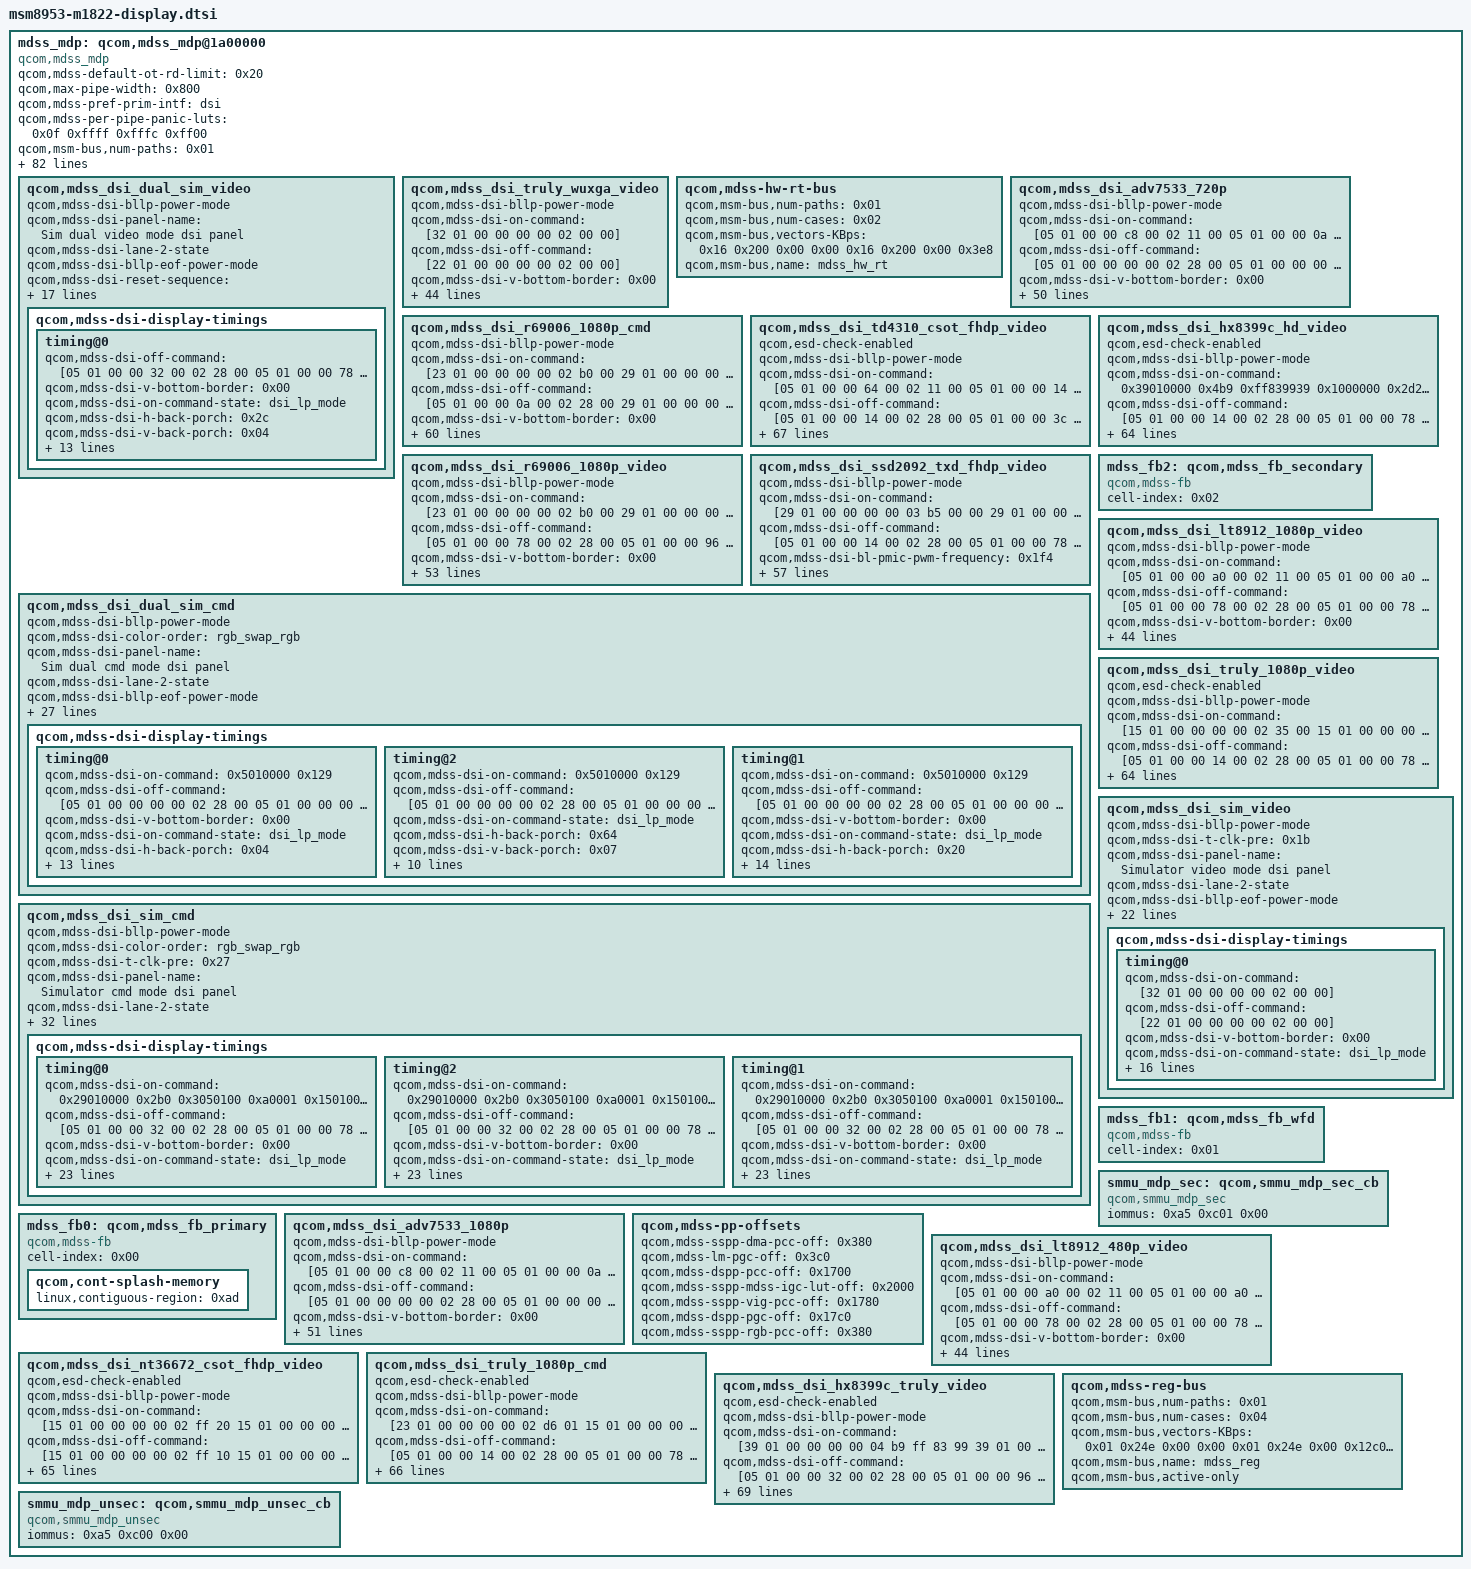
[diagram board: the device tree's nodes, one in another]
		mdss_mdp: qcom,mdss_mdp@1a00000 {
			qcom,mdss-default-ot-rd-limit = <0x20>;
			qcom,max-pipe-width = <0x800>;
			qcom,mdss-pref-prim-intf = "dsi";
			qcom,mdss-per-pipe-panic-luts = <0x0f 0xffff 0xfffc 0xff00>;
			qcom,msm-bus,num-paths = <0x01>;
			qcom,msm-bus,num-cases = <0x03>;
			qcom,mdss-wb-off = <0x65000 0x66000>;
			qcom,mdss-pipe-dma-xin-id = <0x02>;
			qcom,regs-dump-mdp = <0x1000 0x1454 0x2000 0x2064 0x2200 0x2264 0x2400 0x2464 0x5000 0x5150 0x5200 0x5230 0x15000 0x15150 0x17000 0x17150 0x25000 0x25150 0x35000 0x35150 0x45000 0x452bc 0x46000 0x462bc 0x55000 0x5522c 0x65000 0x652c0 0x66000 0x662c0 0x6b800 0x6ba68 0x6c000 0x6c268 0x71000 0x710d4 0x71800 0x718d4>;
			compatible = "qcom,mdss_mdp";
			qcom,mdss-prefill-pingpong-buffer-pixels = <0x1000>;
			clocks = <0x29 0xbfb92ed3 0x29 0x668f51de 0x29 0x6dc1f8f1 0xac 0x588460a4 0x29 0x32a09f1f>;
			qcom,mdss-default-ot-wr-limit = <0x10>;
			qcom,msm-bus,vectors-KBps = <0x16 0x200 0x00 0x00 0x16 0x200 0x00 0x61a800 0x16 0x200 0x00 0x61a800>;
			qcom,mdss-vbif-qos-nrt-setting = <0x01 0x01 0x01 0x01>;
			qcom,mdss-has-pingpong-split;
			reg-names = "mdp_phys", "vbif_phys";
			qcom,regs-dump-names-mdp = "MDP", "CTL_0", "CTL_1", "CTL_2", "VIG0_SSPP", "VIG0", "RGB0_SSPP", "RGB1_SSPP", "DMA0_SSPP", "CURSOR0_SSPP", "LAYER_0", "LAYER_1", "DSPP_0", "WB_0", "WB_2", "INTF_1", "INTF_2", "PP_0", "PP_1";
			qcom,mdss-slave-pingpong-off = "", "\a0";
			qcom,mdss-pipe-vig-off = <0x5000>;
			qcom,mdss-pipe-cursor-off = <0x35000>;
			qcom,max-mixer-width = <0x800>;
			qcom,mdss-pipe-rgb-clk-ctrl-offsets = <0x2ac 0x04 0x08 0x2b4 0x04 0x08>;
			qcom,mdss-ab-factor = <0x01 0x01>;
			qcom,mdss-pipe-rgb-xin-id = <0x01 0x05>;
			qcom,mdss-has-panic-ctrl;
			qcom,mdp-settings = <0x506c 0x00 0x1506c 0x00 0x1706c 0x00 0x2506c 0x00>;
			qcom,mdss-idle-power-collapse-enabled;
			clock-names = "iface_clk", "bus_clk", "core_clk_src", "core_clk", "vsync_clk";
			qcom,mdss-pipe-vig-xin-id = <0x00>;
			qcom,mdss-prefill-scaler-buffer-lines-bilinear = <0x02>;
			qcom,mdss-cdm-off = <0x7a200>;
			qcom,mdss-pipe-vig-clk-ctrl-offsets = <0x2ac 0x00 0x00>;
			qcom,mdss-pipe-dma-clk-ctrl-offsets = <0x2ac 0x08 0x0c>;
			qcom,mdss-ppb-off = <0x330>;
			qcom,mdss-pipe-cursor-clk-ctrl-offsets = <0x3a8 0x10 0x0f>;
			qcom,msm-bus,name = "mdss_mdp";
			qcom,vbif-settings = <0xd0 0x10>;
			qcom,max-bandwidth-high-kbps = <0x33e140>;
			qcom,max-bandwidth-low-kbps = <0x33e140>;
			qcom,mdss-prefill-y-buffer-bytes = <0x00>;
			qcom,mdss-rot-downscale-min = <0x02>;
			qcom,mdss-dspp-off = <0x55000>;
			interrupts = <0x00 0x48 0x00>;
			qcom,mdss-highest-bank-bit = <0x01>;
			qcom,mdss-prefill-scaler-buffer-lines-caf = <0x04>;
			qcom,mdss-wfd-mode = "intf";
			qcom,mdss-pingpong-off = <0x71000 0x71800>;
			qcom,mdss-has-non-scalar-rgb;
			phandle = <0xb2>;
			qcom,mdss-mixer-intf-off = <0x45000 0x46000>;
			qcom,max-clk-rate = <0x17d78400>;
			qcom,mdss-rot-block-size = <0x40>;
			qcom,mdss-rot-downscale-max = <0x10>;
			qcom,mdss-mdp-reg-offset = <0x1000>;
			qcom,mdss-has-rotator-downscale;
			qcom,mdss-ib-factor = <0x01 0x01>;
			qcom,mdss-has-decimation;
			qcom,mdss-pipe-cursor-xin-id = <0x07>;
			vdd-supply = <0xab>;
			reg = <0x1a00000 0x90000 0x1ab0000 0x1040>;
			qcom,mdss-clk-factor = <0x69 0x64>;
			qcom,mdss-vbif-qos-rt-setting = <0x01 0x02 0x02 0x02>;
			qcom,mdss-intf-off = <0x6b000 0x6b800 0x6c000>;
			qcom,mdss-pipe-dma-off = <0x25000>;
			qcom,mdss-pipe-rgb-off = <0x15000 0x17000>;
			linux,phandle = <0xb2>;
			qcom,mdss-ctl-off = <0x2000 0x2200 0x2400>;
			qcom,max-bw-settings = <0x01 0x33e140 0x02 0x2f4d60>;
			qcom,max-bandwidth-per-pipe-kbps = <0x231860>;
			qcom,mdss-prefill-outstanding-buffer-bytes = <0x00>;
			qcom,mdss-prefill-post-scaler-buffer-pixels = <0x800>;

			qcom,mdss_dsi_dual_sim_video {
				qcom,mdss-dsi-bllp-power-mode;
				qcom,mdss-dsi-panel-name = "Sim dual video mode dsi panel";
				qcom,mdss-dsi-lane-2-state;
				qcom,mdss-dsi-bllp-eof-power-mode;
				qcom,mdss-dsi-reset-sequence = <0x01 0x14 0x00 0xc8 0x01 0x14>;
				qcom,mdss-dsi-dma-trigger = "trigger_sw";
				qcom,mdss-dsi-virtual-channel-id = <0x00>;
				qcom,mdss-dsi-lane-0-state;
				qcom,mdss-dsi-underflow-color = <0xff>;
				qcom,mdss-dsi-lane-3-state;
				qcom,mdss-dsi-border-color = <0x00>;
				qcom,mdss-dsi-mdp-trigger = "none";
				phandle = <0x2ef>;
				qcom,mdss-dsi-bpp = <0x18>;
				qcom,mdss-dsi-panel-type = "dsi_video_mode";
				qcom,mdss-dsi-bl-max-level = <0xfff>;
				qcom,mdss-dsi-lane-1-state;
				qcom,mdss-dsi-stream = <0x00>;
				qcom,mdss-dsi-traffic-mode = "non_burst_sync_event";
				linux,phandle = <0x2ef>;
				qcom,panel-ack-disabled;
				qcom,mdss-dsi-panel-broadcast-mode;

				qcom,mdss-dsi-display-timings {

					timing@0 {
						qcom,mdss-dsi-off-command = [05 01 00 00 32 00 02 28 00 05 01 00 00 78 00 02 10 00];
						qcom,mdss-dsi-v-bottom-border = <0x00>;
						qcom,mdss-dsi-on-command-state = "dsi_lp_mode";
						qcom,mdss-dsi-h-back-porch = <0x2c>;
						qcom,mdss-dsi-v-back-porch = <0x04>;
						qcom,mdss-dsi-panel-width = <0x500>;
						qcom,mdss-dsi-h-sync-skew = <0x00>;
						qcom,mdss-dsi-h-front-porch = <0x78>;
						qcom,mdss-dsi-v-front-porch = <0x08>;
						qcom,mdss-dsi-v-top-border = <0x00>;
						qcom,mdss-dsi-panel-height = <0x5a0>;
						qcom,mdss-dsi-h-sync-pulse = <0x00>;
						qcom,mdss-dsi-h-left-border = <0x00>;
						qcom,mdss-dsi-off-command-state = "dsi_hs_mode";
						qcom,mdss-dsi-panel-framerate = <0x3c>;
						qcom,mdss-dsi-h-pulse-width = <0x10>;
						qcom,mdss-dsi-v-pulse-width = <0x04>;
						qcom,mdss-dsi-h-right-border = <0x00>;
					};
				};
			};

			qcom,mdss_dsi_truly_wuxga_video {
				qcom,mdss-dsi-bllp-power-mode;
				qcom,mdss-dsi-on-command = [32 01 00 00 00 00 02 00 00];
				qcom,mdss-dsi-off-command = [22 01 00 00 00 00 02 00 00];
				qcom,mdss-dsi-v-bottom-border = <0x00>;
				qcom,mdss-dsi-t-clk-pre = <0x2d>;
				qcom,mdss-dsi-bl-min-level = <0x01>;
				qcom,mdss-dsi-on-command-state = "dsi_hs_mode";
				qcom,mdss-dsi-h-back-porch = <0x40>;
				qcom,mdss-dsi-v-back-porch = <0x10>;
				qcom,mdss-dsi-panel-name = "truly wuxga video mode dsi panel";
				qcom,mdss-dsi-lane-2-state;
				qcom,mdss-dsi-bllp-eof-power-mode;
				qcom,mdss-dsi-panel-width = <0x780>;
				qcom,mdss-dsi-h-sync-skew = <0x00>;
				qcom,mdss-dsi-reset-sequence = <0x01 0xc8 0x00 0xc8 0x01 0xc8>;
				qcom,mdss-dsi-h-front-porch = <0x60>;
				qcom,mdss-dsi-v-front-porch = <0x04>;
				qcom,mdss-dsi-dma-trigger = "trigger_sw";
				qcom,mdss-dsi-v-top-border = <0x00>;
				qcom,mdss-dsi-panel-height = <0x4b0>;
				qcom,mdss-dsi-h-sync-pulse = <0x00>;
				qcom,mdss-dsi-virtual-channel-id = <0x00>;
				qcom,mdss-dsi-lane-0-state;
				qcom,mdss-dsi-panel-timings-phy-v2 = <0x241f0809 0x50304a0 0x241f0809 0x50304a0 0x241f0809 0x50304a0 0x241f0809 0x50304a0 0x241c0809 0x50304a0>;
				qcom,mdss-dsi-underflow-color = <0xff>;
				qcom,mdss-dsi-lane-3-state;
				qcom,mdss-dsi-h-left-border = <0x00>;
				qcom,mdss-dsi-border-color = <0x00>;
				qcom,mdss-dsi-mdp-trigger = "none";
				phandle = <0x2f6>;
				qcom,mdss-dsi-bpp = <0x18>;
				qcom,mdss-dsi-panel-type = "dsi_video_mode";
				qcom,mdss-dsi-off-command-state = "dsi_lp_mode";
				qcom,mdss-dsi-panel-framerate = <0x3c>;
				qcom,mdss-dsi-bl-max-level = <0xfff>;
				qcom,mdss-dsi-lane-1-state;
				qcom,mdss-dsi-h-pulse-width = <0x10>;
				qcom,mdss-dsi-v-pulse-width = <0x01>;
				qcom,mdss-dsi-bl-pmic-control-type = "bl_ctrl_wled";
				qcom,mdss-dsi-stream = <0x00>;
				qcom,mdss-dsi-traffic-mode = "burst_mode";
				linux,phandle = <0x2f6>;
				qcom,mdss-dsi-h-right-border = <0x00>;
				qcom,mdss-dsi-t-clk-post = <0x02>;
				qcom,mdss-dsi-panel-timings = <0xf33a2600 0x6c6e2c3e 0x2f030400>;
			};

			qcom,mdss-hw-rt-bus {
				qcom,msm-bus,num-paths = <0x01>;
				qcom,msm-bus,num-cases = <0x02>;
				qcom,msm-bus,vectors-KBps = <0x16 0x200 0x00 0x00 0x16 0x200 0x00 0x3e8>;
				qcom,msm-bus,name = "mdss_hw_rt";
			};

			qcom,mdss_dsi_adv7533_720p {
				qcom,mdss-dsi-bllp-power-mode;
				qcom,mdss-dsi-on-command = [05 01 00 00 c8 00 02 11 00 05 01 00 00 0a 00 02 29 00];
				qcom,mdss-dsi-off-command = [05 01 00 00 00 00 02 28 00 05 01 00 00 00 00 02 10 00];
				qcom,mdss-dsi-v-bottom-border = <0x00>;
				qcom,mdss-dsi-t-clk-pre = <0x20>;
				qcom,mdss-dsi-bl-min-level = <0x01>;
				qcom,mdss-dsi-on-command-state = "dsi_lp_mode";
				qcom,mdss-dsi-h-back-porch = <0xdc>;
				qcom,mdss-dsi-v-back-porch = <0x14>;
				qcom,mdss-dsi-panel-name = "dsi_adv7533_720p";
				qcom,mdss-dsi-lane-2-state;
				qcom,mdss-dsi-bllp-eof-power-mode;
				qcom,mdss-dsi-panel-width = <0x500>;
				qcom,mdss-dsi-h-sync-skew = <0x00>;
				qcom,mdss-dsi-reset-sequence = <0x01 0x14 0x00 0x01 0x01 0x14>;
				qcom,mdss-dsi-h-front-porch = <0x6e>;
				qcom,mdss-dsi-v-front-porch = <0x05>;
				qcom,mdss-dsi-dma-trigger = "trigger_sw";
				qcom,mdss-dsi-panel-destination = "display_1";
				qcom,mdss-dsi-v-top-border = <0x00>;
				qcom,mdss-dsi-panel-height = <0x2d0>;
				qcom,mdss-dsi-h-sync-pulse = <0x01>;
				qcom,mdss-dsi-virtual-channel-id = <0x00>;
				qcom,mdss-dsi-lane-0-state;
				qcom,mdss-dsi-panel-timings-phy-v2 = <0x1e1b0406 0x20304a0 0x1e1b0406 0x20304a0 0x1e1b0406 0x20304a0 0x1e1b0406 0x20304a0 0x1e0e0405 0x20304a0>;
				qcom,mdss-dsi-underflow-color = <0xff>;
				qcom,mdss-dsi-h-left-border = <0x00>;
				qcom,mdss-dsi-border-color = <0x00>;
				qcom,mdss-pan-physical-width-dimension = <0xa0>;
				qcom,mdss-dsi-mdp-trigger = "none";
				label = "adv7533 720p video mode dsi panel";
				phandle = <0x2f3>;
				qcom,mdss-dsi-bpp = <0x18>;
				qcom,mdss-dsi-panel-type = "dsi_video_mode";
				qcom,mdss-pan-physical-height-dimension = <0x5a>;
				qcom,mdss-dsi-off-command-state = "dsi_hs_mode";
				qcom,mdss-dsi-panel-framerate = <0x3c>;
				qcom,dba-panel;
				qcom,mdss-dsi-bl-max-level = <0xfff>;
				qcom,mdss-dsi-lane-1-state;
				qcom,mdss-dsi-h-pulse-width = <0x28>;
				qcom,mdss-dsi-v-pulse-width = <0x05>;
				qcom,mdss-dsi-force-clock-lane-hs;
				qcom,mdss-dsi-stream = <0x00>;
				qcom,mdss-dsi-traffic-mode = "non_burst_sync_pulse";
				linux,phandle = <0x2f3>;
				qcom,mdss-dsi-always-on;
				qcom,mdss-dsi-h-right-border = <0x00>;
				qcom,mdss-dsi-t-clk-post = <0x03>;
				qcom,mdss-dsi-panel-controller = <0x252>;
				qcom,bridge-name = "adv7533";
				qcom,mdss-dsi-panel-timings = <0xa4241800 0x4e521c28 0x1c030400>;
			};

			qcom,mdss_dsi_r69006_1080p_cmd {
				qcom,mdss-dsi-bllp-power-mode;
				qcom,mdss-dsi-on-command = [23 01 00 00 00 00 02 b0 00 29 01 00 00 00 00 06 b3 04 10 00 00 00 29 01 00 00 00 00 03 b4 0c 00 29 01 00 00 00 00 04 b6 3b d3 00 23 01 00 00 00 00 02 c0 00 15 01 00 00 00 00 02 36 98 23 01 00 00 00 00 02 cc 04 29 01 00 00 00 00 20 c1 84 00 10 ef 8b f1 ff ff df 9c c5 9a 73 8d ad 63 fe ff ff cb f8 01 00 aa 40 02 c2 01 08 00 01 29 01 00 00 00 00 0a cb 0d fe 1f 2c 00 00 00 00 00 29 01 00 00 00 00 0b c2 01 f7 80 04 63 00 60 00 01 30 29 01 00 00 00 00 07 c3 55 01 00 01 00 00 29 01 00 00 00 00 12 c4 70 00 00 00 00 00 00 00 00 02 01 00 05 01 00 00 00 29 01 00 00 00 00 0f c6 57 07 4a 07 4a 01 0e 01 02 01 02 09 15 07 29 01 00 00 00 00 1f c7 00 06 0c 16 27 35 3f 4d 33 3c 49 5b 64 66 67 00 06 0c 16 27 35 3f 4d 33 3c 49 5b 64 66 67 29 01 00 00 00 00 14 c8 00 00 fe 01 08 e7 00 00 fd 02 03 a8 00 00 fc e7 e9 c9 00 29 01 00 00 00 00 09 c9 1f 68 1f 68 4c 4c c4 11 29 01 00 00 00 00 11 d0 11 01 91 0b d9 19 19 00 00 00 19 99 00 00 00 00 29 01 00 00 00 00 1d d3 1b 3b bb ad a5 33 33 33 00 80 ad a8 37 33 33 33 33 f7 f2 1f 7d 7c ff 0f 99 00 ff ff 29 01 00 00 00 00 04 d4 57 33 03 29 01 00 00 00 00 0c d5 66 00 00 01 32 01 32 00 0b 00 0b 29 01 00 00 00 00 02 be 04 29 01 00 00 00 00 11 cf 40 10 00 00 00 00 32 00 00 00 00 00 00 00 00 00 29 01 00 00 00 00 06 de 00 00 3f ff 10 29 01 00 00 00 00 02 e9 00 29 01 00 00 00 00 02 f2 00 23 01 00 00 00 00 02 d6 01 39 01 00 00 00 00 02 35 00 39 01 00 00 00 00 02 51 ff 39 01 00 00 00 00 02 53 2c 39 01 00 00 00 00 02 55 00 05 01 00 00 78 00 02 11 00 05 01 00 00 14 00 02 29 00];
				qcom,mdss-dsi-off-command = [05 01 00 00 0a 00 02 28 00 29 01 00 00 00 00 1d d3 13 3b bb a5 a5 33 33 33 00 80 a4 a8 37 33 33 33 33 f7 f2 1f 7d 7c ff 0f 99 00 ff ff 05 01 00 00 5a 00 02 10 00];
				qcom,mdss-dsi-v-bottom-border = <0x00>;
				qcom,mdss-dsi-t-clk-pre = <0x30>;
				qcom,mdss-dsi-bl-min-level = <0x01>;
				qcom,mdss-dsi-on-command-state = "dsi_lp_mode";
				qcom,mdss-dsi-h-back-porch = <0x52>;
				qcom,mdss-dsi-v-back-porch = <0x09>;
				qcom,mdss-dsi-panel-name = "r69006 1080p cmd mode dsi panel";
				qcom,mdss-dsi-lane-2-state;
				qcom,mdss-dsi-bllp-eof-power-mode;
				qcom,mdss-dsi-panel-status-check-mode = "reg_read";
				qcom,mdss-dsi-panel-width = <0x438>;
				qcom,mdss-dsi-h-sync-skew = <0x00>;
				qcom,mdss-dsi-panel-status-command-mode = "dsi_lp_mode";
				qcom,mdss-dsi-reset-sequence = <0x01 0x0a 0x00 0x0a 0x01 0x0a>;
				qcom,mdss-dsi-panel-max-error-count = <0x03>;
				qcom,mdss-dsi-te-check-enable;
				qcom,mdss-dsi-tx-eot-append;
				qcom,mdss-dsi-te-pin-select = <0x01>;
				qcom,mdss-dsi-te-using-te-pin;
				qcom,mdss-dsi-h-front-porch = <0x64>;
				qcom,mdss-dsi-v-front-porch = <0x03>;
				qcom,mdss-dsi-dma-trigger = "trigger_sw";
				qcom,mdss-dsi-v-top-border = <0x00>;
				qcom,mdss-dsi-panel-status-command = <0x6010001 0x500010a>;
				qcom,mdss-dsi-panel-height = <0x780>;
				qcom,mdss-dsi-te-dcs-command = <0x01>;
				qcom,mdss-dsi-virtual-channel-id = <0x00>;
				qcom,mdss-dsi-lane-0-state;
				qcom,mdss-dsi-panel-timings-phy-v2 = <0x241f0809 0x50304a0 0x241f0809 0x50304a0 0x241f0809 0x50304a0 0x241f0809 0x50304a0 0x241b0809 0x50304a0>;
				qcom,mdss-dsi-underflow-color = <0xff>;
				qcom,mdss-dsi-panel-status-read-length = <0x01>;
				qcom,mdss-dsi-lane-3-state;
				qcom,mdss-dsi-h-left-border = <0x00>;
				qcom,mdss-dsi-border-color = <0x00>;
				qcom,mdss-dsi-mdp-trigger = "none";
				phandle = <0x2f5>;
				qcom,mdss-dsi-bpp = <0x18>;
				qcom,mdss-dsi-panel-type = "dsi_cmd_mode";
				qcom,mdss-dsi-panel-status-value = <0x1c>;
				qcom,mdss-dsi-wr-mem-continue = <0x3c>;
				qcom,mdss-dsi-off-command-state = "dsi_hs_mode";
				qcom,mdss-dsi-panel-framerate = <0x3c>;
				qcom,mdss-dsi-bl-max-level = <0xfff>;
				qcom,mdss-dsi-lane-1-state;
				qcom,mdss-dsi-h-pulse-width = <0x14>;
				qcom,mdss-dsi-v-pulse-width = <0x0f>;
				qcom,mdss-dsi-bl-pmic-control-type = "bl_ctrl_wled";
				qcom,mdss-dsi-stream = <0x00>;
				qcom,mdss-dsi-traffic-mode = "burst_mode";
				linux,phandle = <0x2f5>;
				qcom,mdss-dsi-h-right-border = <0x00>;
				qcom,mdss-dsi-t-clk-post = <0x1e>;
				qcom,mdss-dsi-rx-eot-ignore;
				qcom,mdss-dsi-panel-timings = <0x6e3f3600 0x5a4f3841 0x54030400>;
				qcom,mdss-dsi-wr-mem-start = <0x2c>;
			};

			qcom,mdss_dsi_td4310_csot_fhdp_video {
				qcom,esd-check-enabled;
				qcom,mdss-dsi-bllp-power-mode;
				qcom,mdss-dsi-on-command = [05 01 00 00 64 00 02 11 00 05 01 00 00 14 00 02 29 00];
				qcom,mdss-dsi-off-command = [05 01 00 00 14 00 02 28 00 05 01 00 00 3c 00 02 10 00];
				qcom,mdss-dsi-bl-pmic-pwm-frequency = <0x1f4>;
				qcom,mdss-dsi-v-bottom-border = <0x00>;
				qcom,mdss-dsi-color-order = "rgb_swap_rgb";
				qcom,mdss-dsi-t-clk-pre = <0x30>;
				qcom,mdss-dsi-bl-min-level = <0x02>;
				qcom,mdss-dsi-bl-pmic-control-type = "bl_ctrl_wled";
				qcom,mdss-dsi-on-command-state = "dsi_lp_mode";
				qcom,mdss-dsi-h-back-porch = <0x10>;
				qcom,mdss-dsi-v-back-porch = <0x21>;
				qcom,mdss-dsi-panel-name = "td4310 csot fhdp video mode dsi panel";
				qcom,mdss-dsi-lane-2-state;
				qcom,mdss-dsi-lp11-init;
				qcom,mdss-dsi-bllp-eof-power-mode;
				qcom,mdss-dsi-panel-status-check-mode = "reg_read";
				qcom,mdss-dsi-panel-width = <0x438>;
				qcom,mdss-dsi-h-sync-skew = <0x00>;
				qcom,mdss-dsi-reset-sequence = <0x01 0x05 0x00 0x05 0x01 0x0a>;
				qcom,mdss-dsi-tx-eot-append;
				qcom,suspend-ulps-enabled;
				qcom,mdss-dsi-h-front-porch = <0x38>;
				qcom,mdss-dsi-v-front-porch = <0x04>;
				qcom,mdss-dsi-dma-trigger = "trigger_sw";
				qcom,mdss-dsi-panel-destination = "display_1";
				qcom,mdss-dsi-v-top-border = <0x00>;
				qcom,mdss-dsi-panel-status-command = <0x6010001 0x10a>;
				qcom,mdss-dsi-panel-height = <0x870>;
				qcom,mdss-dsi-h-sync-pulse = <0x01>;
				qcom,mdss-dsi-virtual-channel-id = <0x00>;
				qcom,mdss-dsi-lane-0-state;
				qcom,mdss-dsi-panel-timings-phy-v2 = <0x241f0809 0x50304a0 0x241f0809 0x50304a0 0x241f0809 0x50304a0 0x241f0809 0x50304a0 0x241b0809 0x50304a0>;
				qcom,mdss-dsi-underflow-color = <0xff>;
				qcom,mdss-dsi-panel-status-read-length = <0x01>;
				qcom,mdss-dsi-lane-3-state;
				qcom,mdss-dsi-h-left-border = <0x00>;
				qcom,mdss-dsi-border-color = <0x00>;
				qcom,mdss-pan-physical-width-dimension = <0x44>;
				qcom,mdss-dsi-panel-status-command-state = "dsi_lp_mode";
				qcom,mdss-dsi-mdp-trigger = "none";
				phandle = <0x2ed>;
				qcom,mdss-dsi-bpp = <0x18>;
				qcom,mdss-dsi-bl-pmic-bank-select = <0x00>;
				qcom,mdss-dsi-panel-type = "dsi_video_mode";
				qcom,mdss-dsi-lane-map = "lane_map_0123";
				qcom,mdss-dsi-panel-status-value = <0x1c>;
				qcom,mdss-pan-physical-height-dimension = <0x88>;
				qcom,mdss-dsi-off-command-state = "dsi_lp_mode";
				qcom,mdss-dsi-panel-framerate = <0x3c>;
				qcom,mdss-brightness-max-level = <0x1ff>;
				qcom,mdss-dsi-bl-max-level = <0x1ff>;
				qcom,mdss-dsi-lane-1-state;
				qcom,mdss-dsi-h-pulse-width = <0x04>;
				qcom,mdss-dsi-v-pulse-width = <0x02>;
				qcom,panel-supply-entries = <0x2e8>;
				qcom,mdss-dsi-bl-pmic-control-type = "bl_ctrl_pwm";
				qcom,mdss-dsi-pwm-gpio = <0x14d 0x08 0x00>;
				qcom,mdss-dsi-stream = <0x00>;
				qcom,mdss-dsi-traffic-mode = "burst_mode";
				linux,phandle = <0x2ed>;
				qcom,mdss-dsi-h-right-border = <0x00>;
				qcom,mdss-dsi-t-clk-post = <0x0d>;
				qcom,mdss-dsi-panel-controller = <0x252>;
				qcom,mdss-dsi-panel-timings = <0xf3382600 0x6a6e2c3c 0x2f030400>;
			};

			qcom,mdss_dsi_hx8399c_hd_video {
				qcom,esd-check-enabled;
				qcom,mdss-dsi-bllp-power-mode;
				qcom,mdss-dsi-on-command = <0x39010000 0x4b9 0xff839939 0x1000000 0x2d288 0x39010000 0xcb1 0x2047292 0x132aa11 0x11525739 0x1000000 0x10b200 0x8080cc05 0x75a1110 0x10001e70 0x3d43901 0x00 0x2db400ff 0x595901ab 0x900 0x3050028 0x30b0d21 0x302000c 0xa3805959 0x2ab0000 0x9000305 0x28030b 0xd02000c 0xa3013901 0x500 0x22d3000c 0x3030000 0x10100000 0x3000300 0x8780878 0x00 0x240205 0x5030000 0x54039 0x1000005 0x21d520 0x20191918 0x18020300 0x1242418 0x18181824 0x24000000 0x00 0x2f2f30 0x30313139 0x1000005 0x21d624 0x24181819 0x19010003 0x2242418 0x18181820 0x20404040 0x40404040 0x402f2f30 0x30313139 0x1000000 0x2bd00 0x39010000 0x11d8 0xaaaaaaaa 0xaaaaaaaa 0xaabaaaaa 0xaabaaaaa 0x39010000 0x2bd 0x1390100 0x11 0xd8000000 0x00 0x82eaaa 0xaa82eaaa 0xaa390100 0x02 0xbd023901 0x00 0x9d8ffff 0xc03fffff 0xc03f3901 0x00 0x2bd0039 0x1000005 0x37e001 0x21312d66 0x6f7b757a 0x8186898c 0x9095979a 0xa1a2aa9e 0xadb05b57 0x637a0121 0x312d666f 0x7b757a81 0x86898c90 0x95979aa1 0xa2aa9ead 0xb05b5763 0x7a390100 0x03 0xb67e7e39 0x1000000 0x2cc08 0x39010000 0x235 0x390100 0x02 0xdd030501 0x9600 0x2110005 0x1000014 0x22900>;
				qcom,mdss-dsi-off-command = [05 01 00 00 14 00 02 28 00 05 01 00 00 78 00 02 10 00];
				qcom,mdss-dsi-v-bottom-border = <0x00>;
				qcom,mdss-dsi-color-order = "rgb_swap_rgb";
				qcom,mdss-dsi-t-clk-pre = <0x1d>;
				qcom,mdss-dsi-on-command-state = "dsi_lp_mode";
				qcom,mdss-dsi-h-back-porch = <0x30>;
				qcom,mdss-dsi-v-back-porch = <0x28>;
				qcom,mdss-dsi-panel-name = "hx8399c video mode dsi hd panel";
				qcom,mdss-dsi-lane-2-state;
				qcom,mdss-dsi-lp11-init;
				qcom,mdss-dsi-max-refresh-rate = <0x3c>;
				qcom,mdss-dsi-bllp-eof-power-mode;
				qcom,mdss-dsi-panel-status-check-mode = "reg_read";
				qcom,mdss-dsi-panel-width = <0x2d0>;
				qcom,mdss-dsi-h-sync-skew = <0x00>;
				qcom,mdss-dsi-reset-sequence = <0x01 0x0a 0x00 0x0a 0x01 0x0a>;
				qcom,mdss-dsi-panel-max-error-count = <0x03>;
				qcom,mdss-dsi-pan-enable-dynamic-fps;
				qcom,mdss-dsi-tx-eot-append;
				qcom,mdss-dsi-h-front-porch = <0x30>;
				qcom,mdss-dsi-v-front-porch = <0x24>;
				qcom,mdss-dsi-dma-trigger = "trigger_sw";
				qcom,mdss-dsi-v-top-border = <0x00>;
				qcom,mdss-dsi-pan-fps-update = "dfps_immediate_porch_mode_vfp";
				qcom,mdss-dsi-panel-status-command = <0x6010001 0x10a>;
				qcom,mdss-dsi-panel-height = <0x5a0>;
				qcom,mdss-dsi-h-sync-pulse = <0x00>;
				qcom,mdss-dsi-virtual-channel-id = <0x00>;
				qcom,mdss-dsi-lane-0-state;
				qcom,mdss-dsi-panel-timings-phy-v2 = <0x241f0809 0x50304a0 0x241f0809 0x50304a0 0x241f0809 0x50304a0 0x241f0809 0x50304a0 0x241c0809 0x50304a0>;
				qcom,mdss-dsi-underflow-color = <0xff>;
				qcom,mdss-dsi-panel-status-read-length = <0x04>;
				qcom,mdss-dsi-lane-3-state;
				qcom,mdss-dsi-h-left-border = <0x00>;
				qcom,mdss-dsi-border-color = <0x00>;
				qcom,mdss-dsi-panel-status-command-state = "dsi_lp_mode";
				qcom,mdss-dsi-mdp-trigger = "none";
				phandle = <0x2fa>;
				qcom,mdss-dsi-bpp = <0x18>;
				qcom,mdss-dsi-panel-type = "dsi_video_mode";
				qcom,mdss-dsi-lane-map = "lane_map_0123";
				qcom,mdss-dsi-panel-status-value = <0x9d 0x9d 0x9d 0x9d>;
				qcom,mdss-dsi-off-command-state = "dsi_hs_mode";
				qcom,mdss-dsi-panel-framerate = <0x3c>;
				qcom,mdss-dsi-lane-1-state;
				qcom,mdss-dsi-h-pulse-width = <0x10>;
				qcom,mdss-dsi-v-pulse-width = <0x04>;
				qcom,panel-supply-entries = <0x2e8>;
				qcom,mdss-dsi-min-refresh-rate = <0x37>;
				qcom,mdss-dsi-stream = <0x00>;
				qcom,mdss-dsi-traffic-mode = "non_burst_sync_event";
				linux,phandle = <0x2fa>;
				qcom,mdss-dsi-panel-on-check-value = <0x9d 0x9d 0x9d 0x9d>;
				qcom,mdss-dsi-h-right-border = <0x00>;
				qcom,mdss-dsi-t-clk-post = <0x0a>;
				qcom,mdss-dsi-panel-timings = <0x7a1a1200 0x3e42161e 0x14030400>;
			};

			qcom,mdss_dsi_r69006_1080p_video {
				qcom,mdss-dsi-bllp-power-mode;
				qcom,mdss-dsi-on-command = [23 01 00 00 00 00 02 b0 00 29 01 00 00 00 00 06 b3 05 10 00 00 00 29 01 00 00 00 00 03 b4 0c 00 29 01 00 00 00 00 04 b6 3b c3 00 23 01 00 00 00 00 02 c0 00 15 01 00 00 00 00 02 36 98 23 01 00 00 00 00 02 cc 04 29 01 00 00 00 00 20 c1 84 00 10 ef 8b f1 ff ff df 9c c5 9a 73 8d ad 63 fe ff ff cb f8 01 00 aa 40 00 c2 01 08 00 01 29 01 00 00 00 00 0a cb 0d fe 1f 2c 00 00 00 00 00 29 01 00 00 00 00 0b c2 01 f7 80 04 63 00 60 00 01 30 29 01 00 00 00 00 07 c3 55 01 00 01 00 00 29 01 00 00 00 00 12 c4 70 00 00 00 00 00 00 00 00 02 01 00 05 01 00 00 00 29 01 00 00 00 00 0f c6 59 07 4a 07 4a 01 0e 01 02 01 02 09 15 07 29 01 00 00 00 00 1f c7 00 30 32 34 42 4e 56 62 44 4a 54 62 6b 73 7f 08 30 32 34 42 4e 56 62 44 4a 54 62 6b 73 7f 29 01 00 00 00 00 14 c8 00 00 00 00 00 fc 00 00 00 00 00 fc 00 00 00 00 00 fc 00 29 01 00 00 00 00 09 c9 1f 68 1f 68 4c 4c c4 11 29 01 00 00 00 00 11 d0 33 01 91 0b d9 19 19 00 00 00 19 99 00 00 00 00 29 01 00 00 00 00 1d d3 1b 3b bb ad a5 33 33 33 00 80 ad a8 6f 6f 33 33 33 f7 f2 1f 7d 7c ff 0f 99 00 ff ff 29 01 00 00 00 00 04 d4 57 33 03 29 01 00 00 00 00 0c d5 66 00 00 01 27 01 27 00 6d 00 6d 23 01 00 00 00 00 02 d6 81 05 01 00 00 78 00 02 11 00 05 01 00 00 78 00 02 29 00];
				qcom,mdss-dsi-off-command = [05 01 00 00 78 00 02 28 00 05 01 00 00 96 00 02 10 00];
				qcom,mdss-dsi-v-bottom-border = <0x00>;
				qcom,mdss-dsi-t-clk-pre = <0x2c>;
				qcom,mdss-dsi-bl-min-level = <0x01>;
				qcom,mdss-dsi-on-command-state = "dsi_lp_mode";
				qcom,mdss-dsi-h-back-porch = <0x52>;
				qcom,mdss-dsi-v-back-porch = <0x09>;
				qcom,mdss-dsi-panel-name = "r69006 1080p video mode dsi panel";
				qcom,mdss-dsi-lane-2-state;
				qcom,mdss-dsi-bllp-eof-power-mode;
				qcom,mdss-dsi-panel-status-check-mode = "reg_read";
				qcom,mdss-dsi-panel-width = <0x438>;
				qcom,mdss-dsi-h-sync-skew = <0x00>;
				qcom,mdss-dsi-panel-status-command-mode = "dsi_lp_mode";
				qcom,mdss-dsi-reset-sequence = <0x01 0x14 0x00 0x02 0x01 0x14>;
				qcom,mdss-dsi-panel-max-error-count = <0x03>;
				qcom,mdss-dsi-h-front-porch = <0x64>;
				qcom,mdss-dsi-v-front-porch = <0x03>;
				qcom,mdss-dsi-dma-trigger = "trigger_sw";
				qcom,mdss-dsi-v-top-border = <0x00>;
				qcom,mdss-dsi-panel-status-command = <0x6010001 0x500010a>;
				qcom,mdss-dsi-panel-height = <0x780>;
				qcom,mdss-dsi-h-sync-pulse = <0x01>;
				qcom,mdss-dsi-virtual-channel-id = <0x00>;
				qcom,mdss-dsi-lane-0-state;
				qcom,mdss-dsi-panel-timings-phy-v2 = <0x241f0809 0x50304a0 0x241f0809 0x50304a0 0x241f0809 0x50304a0 0x241f0809 0x50304a0 0x241b0809 0x50304a0>;
				qcom,mdss-dsi-underflow-color = <0xff>;
				qcom,mdss-dsi-panel-status-read-length = <0x01>;
				qcom,mdss-dsi-lane-3-state;
				qcom,mdss-dsi-h-left-border = <0x00>;
				qcom,mdss-dsi-border-color = <0x00>;
				qcom,mdss-dsi-mdp-trigger = "none";
				phandle = <0x2f4>;
				qcom,mdss-dsi-bpp = <0x18>;
				qcom,mdss-dsi-panel-type = "dsi_video_mode";
				qcom,mdss-dsi-panel-status-value = <0x1c>;
				qcom,mdss-dsi-off-command-state = "dsi_hs_mode";
				qcom,mdss-dsi-panel-framerate = <0x3c>;
				qcom,mdss-dsi-bl-max-level = <0xfff>;
				qcom,mdss-dsi-lane-1-state;
				qcom,mdss-dsi-h-pulse-width = <0x14>;
				qcom,mdss-dsi-v-pulse-width = <0x0f>;
				qcom,mdss-dsi-bl-pmic-control-type = "bl_ctrl_wled";
				qcom,mdss-dsi-stream = <0x00>;
				qcom,mdss-dsi-traffic-mode = "burst_mode";
				linux,phandle = <0x2f4>;
				qcom,mdss-dsi-h-right-border = <0x00>;
				qcom,mdss-dsi-t-clk-post = <0x20>;
				qcom,mdss-dsi-panel-timings = <0x7d251d00 0x37332227 0x1e030400>;
			};

			qcom,mdss_dsi_ssd2092_txd_fhdp_video {
				qcom,mdss-dsi-bllp-power-mode;
				qcom,mdss-dsi-on-command = [29 01 00 00 00 00 03 b5 00 00 29 01 00 00 00 00 03 b3 03 96 29 01 00 00 00 00 03 b4 21 ff 29 01 00 00 00 00 03 e1 00 00 29 01 00 00 00 00 04 e1 03 00 10 29 01 00 00 00 00 03 b0 04 01 29 01 00 00 00 00 03 b0 07 14 29 01 00 00 00 00 03 c6 04 2d 29 01 00 00 00 00 03 b9 0e 44 29 01 00 00 00 00 03 c1 0c 26 29 01 00 00 00 00 03 c1 08 99 29 01 00 00 00 00 03 b9 23 00 29 01 00 00 00 00 03 c2 04 0f 29 01 00 00 00 00 03 b3 19 0b 29 01 00 00 00 00 03 b0 3d c8 29 01 00 00 00 00 03 b3 0f 20 29 01 00 00 00 00 02 36 02 29 01 00 00 00 00 03 c7 01 09 29 01 00 00 00 00 03 b3 15 80 29 01 00 00 00 00 03 b3 1e 02 29 01 00 00 00 00 03 b3 14 c0 29 01 00 00 00 00 03 b3 16 50 29 01 00 00 00 00 03 b3 1c e4 29 01 00 00 00 00 03 b3 28 00 29 01 00 00 00 00 03 b3 24 1f 29 01 00 00 00 00 03 b0 12 00 29 01 00 00 00 00 03 b0 13 16 29 01 00 00 00 00 03 b0 1a 00 29 01 00 00 00 00 03 b0 1b 16 29 01 00 00 00 00 03 c1 0d a5 29 01 00 00 00 00 03 c1 0e a0 29 01 00 00 00 00 17 c3 00 10 21 2e 37 4a 58 69 75 8c 9e a7 a7 ae b3 bd cc cf 58 57 68 7f 29 01 00 00 00 00 17 c3 15 10 21 2e 37 4a 58 69 75 8c 9e a7 a7 ae b3 bd cc cf 58 57 68 7f 29 01 00 00 00 00 03 bb 01 44 29 01 00 00 00 00 03 bb 02 48 29 01 00 00 00 00 03 bb 03 23 29 01 00 00 00 00 03 bb 04 51 29 01 00 00 00 00 03 bb 05 04 29 01 00 00 00 00 03 bb 06 44 29 01 00 00 00 00 03 bb 07 44 29 01 00 00 00 00 03 bb 08 4e 29 01 00 00 00 00 03 bb 09 dc 29 01 00 00 00 00 03 bb 0a 0c 29 01 00 00 00 00 03 bb 0b 20 29 01 00 00 00 00 03 bb 0c 00 29 01 00 00 00 00 03 bb 0d 33 29 01 00 00 00 00 03 bb 0e 48 29 01 00 00 00 00 03 bb 0f 23 29 01 00 00 00 00 03 bb 10 51 29 01 00 00 00 00 03 bb 11 04 29 01 00 00 00 00 03 bb 12 44 29 01 00 00 00 00 03 bb 13 44 29 01 00 00 00 00 03 bb 14 4e 29 01 00 00 00 00 03 bb 15 dc 29 01 00 00 00 00 03 bb 16 cc 29 01 00 00 00 00 03 bb 17 20 29 01 00 00 00 00 03 bb 18 00 29 01 00 00 00 00 03 bd 2e 00 29 01 00 00 00 00 03 bd 2f 00 29 01 00 00 00 00 03 bd 31 22 29 01 00 00 00 00 03 bd 34 00 29 01 00 00 00 00 03 bd 35 00 29 01 00 00 00 00 03 bd 37 22 29 01 00 00 00 00 03 bd 04 04 29 01 00 00 00 00 03 bd 06 04 29 01 00 00 00 00 03 bd 1a 35 29 01 00 00 00 00 03 bd 1b 53 29 01 00 00 00 00 03 bd 1c 01 29 01 00 00 00 00 03 bd 1d 02 29 01 00 00 00 00 03 bd 1e 02 29 01 00 00 00 00 03 bd 21 00 29 01 00 00 00 00 03 bd 23 24 29 01 00 00 00 00 03 bd 24 42 29 01 00 00 00 00 03 bd 25 01 29 01 00 00 00 00 03 bd 26 02 29 01 00 00 00 00 03 bd 27 02 29 01 00 00 00 00 03 bd 2a 00 29 01 00 00 00 00 03 bd 3a 1d 29 01 00 00 00 00 03 bd 3b 1d 29 01 00 00 00 00 03 bd 3c 1d 29 01 00 00 00 00 03 bd 3d 1d 29 01 00 00 00 00 03 bd 40 aa 29 01 00 00 00 00 03 bd 3f 00 29 01 00 00 00 00 03 bd 41 00 29 01 00 00 00 00 03 bd 42 1d 29 01 00 00 00 00 03 bd 43 1d 29 01 00 00 00 00 03 bd 44 1d 29 01 00 00 00 00 03 bd 45 1d 29 01 00 00 00 00 03 bd 48 aa 29 01 00 00 00 00 03 bd 47 00 29 01 00 00 00 00 03 bd 49 00 29 01 00 00 00 00 03 ba 03 02 29 01 00 00 00 00 03 bc 1e 74 29 01 00 00 00 00 03 bc 24 83 29 01 00 00 00 00 03 bd 2c 33 29 01 00 00 00 00 03 bd 2d 33 29 01 00 00 00 00 03 bd 00 f4 29 01 00 00 00 00 03 bd 01 f0 29 01 00 00 00 00 03 bd 02 f4 29 01 00 00 00 00 03 bd 03 f0 29 01 00 00 00 00 03 bd 0a 00 29 01 00 00 00 00 03 bd 0e 3e 29 01 00 00 00 00 03 bb 19 44 29 01 00 00 00 00 03 bb 1a 49 29 01 00 00 00 00 03 bb 1b 32 29 01 00 00 00 00 03 bb 1c 53 29 01 00 00 00 00 03 bb 1d 24 29 01 00 00 00 00 03 bb 1e 44 29 01 00 00 00 00 03 bb 1f 44 29 01 00 00 00 00 03 bb 20 4e 29 01 00 00 00 00 03 bb 21 dc 29 01 00 00 00 00 03 bb 22 0c 29 01 00 00 00 00 03 bb 23 20 29 01 00 00 00 00 03 bb 24 00 29 01 00 00 00 00 03 bb 25 33 29 01 00 00 00 00 03 bb 26 49 29 01 00 00 00 00 03 bb 27 32 29 01 00 00 00 00 03 bb 28 53 29 01 00 00 00 00 03 bb 29 24 29 01 00 00 00 00 03 bb 2a 44 29 01 00 00 00 00 03 bb 2b 44 29 01 00 00 00 00 03 bb 2c 4e 29 01 00 00 00 00 03 bb 2d dc 29 01 00 00 00 00 03 bb 2e 0c 29 01 00 00 00 00 03 bb 2f 20 29 01 00 00 00 00 03 bb 30 00 29 01 00 00 00 00 04 c6 00 03 40 29 01 00 00 00 00 03 b3 18 00 29 01 00 00 00 00 03 ba 17 28 29 01 00 00 00 00 03 ba 23 15 29 01 00 00 00 00 03 b0 06 2c 29 01 00 00 00 00 03 ba 17 28 29 01 00 00 00 00 03 ba 23 15 29 01 00 00 00 00 03 ba 16 00 29 01 00 00 00 00 04 ba 28 02 02 29 01 00 00 00 00 03 ba 0f 8c 29 01 00 00 00 00 03 ba 10 0c 29 01 00 00 00 00 03 ba 11 1e 29 01 00 00 00 00 05 ba 12 9d 9d 9d 29 01 00 00 00 00 03 ba 25 1c 29 01 00 00 00 00 04 ba 0d 40 02 29 01 00 00 00 00 03 ba 2f 8c 29 01 00 00 00 00 03 c2 04 01 29 01 00 00 00 00 0b b9 11 00 00 00 00 00 00 00 00 00 29 01 00 00 00 00 03 ba 15 33 29 01 00 00 00 00 03 bd 08 02 29 01 00 00 00 00 03 bd 0c 04 29 01 00 00 00 00 03 bd 09 00 29 01 00 00 00 00 03 bd 0d 2f 29 01 00 00 00 00 03 bc 03 03 29 01 00 00 00 00 03 bc 04 00 29 01 00 00 00 00 03 bc 05 00 29 01 00 00 00 00 03 bc 07 10 29 01 00 00 00 00 03 bc 08 11 29 01 00 00 00 00 03 bc 09 14 29 01 00 00 00 00 03 b9 11 53 29 01 00 00 00 00 03 b9 12 35 29 01 00 00 00 00 03 b9 13 33 29 01 00 00 00 00 03 b9 1d 99 29 01 00 00 00 00 03 b9 1e 99 29 01 00 00 00 00 03 b9 1f 99 29 01 00 00 00 00 03 b8 15 a2 29 01 00 00 00 00 03 b8 1b f2 29 01 00 00 00 00 03 b8 16 af 29 01 00 00 00 00 03 b8 1c af 29 01 00 00 00 00 03 b8 17 fa 29 01 00 00 00 00 03 e1 07 12 29 01 00 00 00 00 03 e1 08 10 29 01 00 00 00 00 03 b8 0e 00 29 01 00 00 00 00 03 b8 11 00 29 01 00 00 00 00 03 ec 01 45 29 01 00 00 00 00 03 ec 02 00 29 01 00 00 00 00 03 ec 02 04 29 01 00 00 00 00 03 b1 05 2f 29 01 00 00 00 00 02 35 00 29 01 00 00 00 00 04 b0 01 08 70 29 01 00 00 00 00 03 c2 00 07 29 01 00 00 00 00 06 b9 00 62 62 62 0a 29 01 00 00 00 00 03 b9 0b 02 29 01 00 00 00 00 03 b9 0d 44 29 01 00 00 00 00 03 b9 0e 44 29 01 00 00 00 00 03 c1 02 b0 29 01 00 00 00 00 03 b3 1c c4 29 01 00 00 00 00 03 b3 1d 80 29 01 00 00 00 00 04 bd 11 02 22 05 01 00 00 00 00 02 11 00 05 01 00 00 32 00 02 29 00];
				qcom,mdss-dsi-off-command = [05 01 00 00 14 00 02 28 00 05 01 00 00 78 00 02 10 00];
				qcom,mdss-dsi-bl-pmic-pwm-frequency = <0x1f4>;
				qcom,mdss-dsi-v-bottom-border = <0x00>;
				qcom,mdss-dsi-color-order = "rgb_swap_rgb";
				qcom,mdss-dsi-t-clk-pre = <0x2d>;
				qcom,mdss-dsi-bl-min-level = <0x01>;
				qcom,mdss-dsi-on-command-state = "dsi_lp_mode";
				qcom,mdss-dsi-h-back-porch = <0x14>;
				qcom,mdss-dsi-v-back-porch = <0x2b>;
				qcom,mdss-dsi-panel-name = "ssd2092 txd fhdp video mode dsi panel";
				qcom,mdss-dsi-lane-2-state;
				qcom,mdss-dsi-lp11-init;
				qcom,mdss-dsi-bllp-eof-power-mode;
				qcom,mdss-dsi-panel-width = <0x438>;
				qcom,mdss-dsi-h-sync-skew = <0x00>;
				qcom,mdss-dsi-reset-sequence = <0x01 0x05 0x00 0x14 0x01 0x78>;
				qcom,mdss-dsi-tx-eot-append;
				qcom,mdss-dsi-h-front-porch = <0x14>;
				qcom,mdss-dsi-v-front-porch = <0x4c>;
				qcom,mdss-dsi-dma-trigger = "trigger_sw";
				qcom,mdss-dsi-panel-destination = "display_1";
				qcom,mdss-dsi-v-top-border = <0x00>;
				qcom,mdss-dsi-panel-height = <0x870>;
				qcom,mdss-dsi-h-sync-pulse = <0x01>;
				qcom,mdss-dsi-virtual-channel-id = <0x00>;
				qcom,mdss-dsi-lane-0-state;
				qcom,mdss-dsi-panel-timings-phy-v2 = <0x241f0809 0x50304a0 0x241f0809 0x50304a0 0x241f0809 0x50304a0 0x241f0809 0x50304a0 0x241c0809 0x50304a0>;
				qcom,mdss-dsi-underflow-color = <0xff>;
				qcom,mdss-dsi-lane-3-state;
				qcom,mdss-dsi-h-left-border = <0x00>;
				qcom,mdss-dsi-border-color = <0x00>;
				qcom,mdss-pan-physical-width-dimension = <0x44>;
				qcom,mdss-dsi-mdp-trigger = "none";
				phandle = <0x2ee>;
				qcom,mdss-dsi-bpp = <0x18>;
				qcom,mdss-dsi-bl-pmic-bank-select = <0x00>;
				qcom,mdss-dsi-panel-type = "dsi_video_mode";
				qcom,mdss-dsi-lane-map = "lane_map_0123";
				qcom,mdss-pan-physical-height-dimension = <0x88>;
				qcom,mdss-dsi-off-command-state = "dsi_hs_mode";
				qcom,mdss-dsi-panel-framerate = <0x3c>;
				qcom,mdss-brightness-max-level = <0x1ff>;
				qcom,mdss-dsi-bl-max-level = <0x1ff>;
				qcom,mdss-dsi-lane-1-state;
				qcom,mdss-dsi-h-pulse-width = <0x04>;
				qcom,mdss-dsi-v-pulse-width = <0x01>;
				qcom,panel-supply-entries = <0x2e8>;
				qcom,mdss-dsi-bl-pmic-control-type = "bl_ctrl_pwm";
				qcom,mdss-dsi-pwm-gpio = <0x14d 0x08 0x00>;
				qcom,mdss-dsi-stream = <0x00>;
				qcom,mdss-dsi-traffic-mode = "burst_mode";
				linux,phandle = <0x2ee>;
				qcom,mdss-dsi-h-right-border = <0x00>;
				qcom,mdss-dsi-t-clk-post = <0x02>;
				qcom,mdss-dsi-panel-controller = <0x252>;
				qcom,mdss-dsi-panel-timings = <0xf23a2800 0x6c6e2c3e 0x2e030400>;
			};

			mdss_fb2: qcom,mdss_fb_secondary {
				compatible = "qcom,mdss-fb";
				phandle = <0xb1>;
				linux,phandle = <0xb1>;
				cell-index = <0x02>;
			};

			qcom,mdss_dsi_dual_sim_cmd {
				qcom,mdss-dsi-bllp-power-mode;
				qcom,mdss-dsi-color-order = "rgb_swap_rgb";
				qcom,mdss-dsi-panel-name = "Sim dual cmd mode dsi panel";
				qcom,mdss-dsi-lane-2-state;
				qcom,mdss-dsi-bllp-eof-power-mode;
				qcom,mdss-dsi-reset-sequence = <0x01 0x0a 0x00 0x0a 0x01 0x0a>;
				qcom,mdss-dsi-te-check-enable;
				qcom,mdss-dsi-te-using-wd;
				qcom,mdss-dsi-te-pin-select = <0x01>;
				qcom,mdss-dsi-te-using-te-pin;
				qcom,mdss-dsi-dma-trigger = "trigger_sw";
				qcom,mdss-dsi-te-dcs-command = <0x01>;
				qcom,mdss-dsi-virtual-channel-id = <0x00>;
				qcom,mdss-dsi-lane-0-state;
				qcom,mdss-dsi-underflow-color = <0xff>;
				qcom,mdss-dsi-lane-3-state;
				qcom,mdss-dsi-border-color = <0x00>;
				qcom,mdss-dsi-mdp-trigger = "none";
				qcom,mdss-dsi-hor-line-idle = <0x00 0x28 0x100 0x28 0x78 0x80 0x78 0xf0 0x40>;
				qcom,cmd-sync-wait-broadcast;
				phandle = <0x2f1>;
				qcom,mdss-dsi-bpp = <0x18>;
				qcom,mdss-dsi-panel-type = "dsi_cmd_mode";
				qcom,mdss-dsi-wr-mem-continue = <0x3c>;
				qcom,mdss-dsi-bl-max-level = <0xfff>;
				qcom,mdss-dsi-lane-1-state;
				qcom,mdss-dsi-stream = <0x00>;
				qcom,mdss-dsi-traffic-mode = "non_burst_sync_event";
				linux,phandle = <0x2f1>;
				qcom,panel-ack-disabled;
				qcom,mdss-dsi-wr-mem-start = <0x2c>;

				qcom,mdss-dsi-display-timings {

					timing@0 {
						qcom,mdss-dsi-on-command = <0x5010000 0x129>;
						qcom,mdss-dsi-off-command = [05 01 00 00 00 00 02 28 00 05 01 00 00 00 00 02 10 00];
						qcom,mdss-dsi-v-bottom-border = <0x00>;
						qcom,mdss-dsi-on-command-state = "dsi_lp_mode";
						qcom,mdss-dsi-h-back-porch = <0x04>;
						qcom,mdss-dsi-v-back-porch = <0x0c>;
						qcom,mdss-dsi-panel-width = <0x21c>;
						qcom,mdss-dsi-h-sync-skew = <0x00>;
						qcom,mdss-dsi-h-front-porch = <0x1c>;
						qcom,mdss-dsi-v-front-porch = <0x0c>;
						qcom,mdss-dsi-v-top-border = <0x00>;
						qcom,mdss-dsi-panel-height = <0x780>;
						qcom,mdss-dsi-h-left-border = <0x00>;
						qcom,mdss-dsi-off-command-state = "dsi_hs_mode";
						qcom,mdss-dsi-panel-framerate = <0x78>;
						qcom,mdss-dsi-h-pulse-width = <0x04>;
						qcom,mdss-dsi-v-pulse-width = <0x02>;
						qcom,mdss-dsi-h-right-border = <0x00>;
					};

					timing@2 {
						qcom,mdss-dsi-on-command = <0x5010000 0x129>;
						qcom,mdss-dsi-off-command = [05 01 00 00 00 00 02 28 00 05 01 00 00 00 00 02 10 00];
						qcom,mdss-dsi-on-command-state = "dsi_lp_mode";
						qcom,mdss-dsi-h-back-porch = <0x64>;
						qcom,mdss-dsi-v-back-porch = <0x07>;
						qcom,mdss-dsi-panel-width = <0x438>;
						qcom,mdss-dsi-h-sync-skew = <0x00>;
						qcom,mdss-dsi-h-front-porch = <0x1e>;
						qcom,mdss-dsi-v-front-porch = <0x08>;
						qcom,mdss-dsi-panel-height = <0xf00>;
						qcom,mdss-dsi-h-sync-pulse = <0x00>;
						qcom,mdss-dsi-off-command-state = "dsi_hs_mode";
						qcom,mdss-dsi-panel-framerate = <0x28>;
						qcom,mdss-dsi-h-pulse-width = <0x04>;
						qcom,mdss-dsi-v-pulse-width = <0x01>;
					};

					timing@1 {
						qcom,mdss-dsi-on-command = <0x5010000 0x129>;
						qcom,mdss-dsi-off-command = [05 01 00 00 00 00 02 28 00 05 01 00 00 00 00 02 10 00];
						qcom,mdss-dsi-v-bottom-border = <0x00>;
						qcom,mdss-dsi-on-command-state = "dsi_lp_mode";
						qcom,mdss-dsi-h-back-porch = <0x20>;
						qcom,mdss-dsi-v-back-porch = <0x07>;
						qcom,mdss-dsi-panel-width = <0x2d0>;
						qcom,mdss-dsi-h-sync-skew = <0x00>;
						qcom,mdss-dsi-h-front-porch = <0x64>;
						qcom,mdss-dsi-v-front-porch = <0x08>;
						qcom,mdss-dsi-v-top-border = <0x00>;
						qcom,mdss-dsi-panel-height = <0xa00>;
						qcom,mdss-dsi-h-sync-pulse = <0x00>;
						qcom,mdss-dsi-h-left-border = <0x00>;
						qcom,mdss-dsi-off-command-state = "dsi_hs_mode";
						qcom,mdss-dsi-panel-framerate = <0x3c>;
						qcom,mdss-dsi-h-pulse-width = <0x10>;
						qcom,mdss-dsi-v-pulse-width = <0x01>;
						qcom,mdss-dsi-h-right-border = <0x00>;
					};
				};
			};

			qcom,mdss_dsi_lt8912_1080p_video {
				qcom,mdss-dsi-bllp-power-mode;
				qcom,mdss-dsi-on-command = [05 01 00 00 a0 00 02 11 00 05 01 00 00 a0 00 02 29 00];
				qcom,mdss-dsi-off-command = [05 01 00 00 78 00 02 28 00 05 01 00 00 78 00 02 10 00];
				qcom,mdss-dsi-v-bottom-border = <0x00>;
				qcom,mdss-dsi-color-order = "rgb_swap_rgb";
				qcom,mdss-dsi-t-clk-pre = <0x2b>;
				qcom,mdss-dsi-on-command-state = "dsi_lp_mode";
				qcom,mdss-dsi-h-back-porch = <0x94>;
				qcom,mdss-dsi-v-back-porch = <0x24>;
				qcom,mdss-dsi-panel-name = "lt8912 1080p video mode dsi panel";
				qcom,mdss-dsi-bllp-eof-power-mode;
				qcom,mdss-dsi-panel-width = <0x780>;
				qcom,mdss-dsi-h-sync-skew = <0x00>;
				qcom,mdss-dsi-reset-sequence = <0x01 0x14 0x00 0x02 0x01 0x14>;
				qcom,mdss-dsi-h-front-porch = <0x58>;
				qcom,mdss-dsi-v-front-porch = <0x04>;
				qcom,mdss-dsi-dma-trigger = "trigger_sw";
				qcom,mdss-dsi-panel-destination = "display_1";
				qcom,mdss-dsi-v-top-border = <0x00>;
				qcom,mdss-dsi-panel-height = <0x438>;
				qcom,mdss-dsi-h-sync-pulse = <0x00>;
				qcom,mdss-dsi-virtual-channel-id = <0x00>;
				qcom,mdss-dsi-lane-0-state;
				qcom,mdss-dsi-panel-timings-phy-v2 = <0x231e0809 0x50304a0 0x231e0809 0x50304a0 0x231e0809 0x50304a0 0x231e0809 0x50304a0 0x231a0809 0x50304a0>;
				qcom,mdss-dsi-underflow-color = <0xff>;
				qcom,mdss-dsi-h-left-border = <0x00>;
				qcom,mdss-dsi-border-color = <0x00>;
				qcom,mdss-dsi-mdp-trigger = "none";
				phandle = <0x2f8>;
				qcom,mdss-dsi-bpp = <0x18>;
				qcom,mdss-dsi-panel-type = "dsi_video_mode";
				qcom,mdss-dsi-lane-map = "lane_map_0123";
				qcom,mdss-dsi-off-command-state = "dsi_lp_mode";
				qcom,mdss-dsi-panel-framerate = <0x3c>;
				qcom,mdss-dsi-lane-1-state;
				qcom,mdss-dsi-h-pulse-width = <0x2c>;
				qcom,mdss-dsi-v-pulse-width = <0x05>;
				qcom,mdss-dsi-force-clock-lane-hs;
				qcom,mdss-dsi-stream = <0x00>;
				qcom,mdss-dsi-traffic-mode = "non_burst_sync_event";
				linux,phandle = <0x2f8>;
				qcom,mdss-dsi-h-right-border = <0x00>;
				qcom,mdss-dsi-t-clk-post = <0x02>;
				qcom,mdss-dsi-post-init-delay = <0x01>;
				qcom,mdss-dsi-panel-timings = <0xe6382600 0x686c2a3a 0x2c030400>;
			};

			qcom,mdss_dsi_sim_cmd {
				qcom,mdss-dsi-bllp-power-mode;
				qcom,mdss-dsi-color-order = "rgb_swap_rgb";
				qcom,mdss-dsi-t-clk-pre = <0x27>;
				qcom,mdss-dsi-panel-name = "Simulator cmd mode dsi panel";
				qcom,mdss-dsi-lane-2-state;
				qcom,mdss-dsi-bllp-eof-power-mode;
				qcom,mdss-dsi-reset-sequence = <0x01 0x0a 0x00 0x0a 0x01 0x0a>;
				qcom,mdss-dsi-te-check-enable;
				qcom,mdss-dsi-te-using-wd;
				qcom,mdss-dsi-te-pin-select = <0x01>;
				qcom,mdss-dsi-te-using-te-pin;
				qcom,mdss-dsi-panel-hdr-enabled;
				qcom,mdss-dsi-dma-trigger = "trigger_sw";
				qcom,ulps-enabled;
				qcom,mdss-dsi-te-dcs-command = <0x01>;
				qcom,mdss-dsi-virtual-channel-id = <0x00>;
				qcom,mdss-dsi-panel-peak-brightness = <0x401640>;
				qcom,mdss-dsi-lane-0-state;
				qcom,mdss-dsi-underflow-color = <0xff>;
				qcom,mdss-dsi-lane-3-state;
				qcom,mdss-dsi-border-color = <0x00>;
				qcom,mdss-dsi-mdp-trigger = "none";
				phandle = <0x2f0>;
				qcom,mdss-dsi-bpp = <0x18>;
				qcom,mdss-dsi-panel-type = "dsi_cmd_mode";
				qcom,mdss-dsi-panel-hdr-color-primaries = <0x38a4 0x3c8c 0x7d00 0x4268 0x3c8c 0x7530 0x1f40 0xbb8>;
				qcom,mdss-dsi-wr-mem-continue = <0x3c>;
				qcom,mdss-dsi-panel-blackness-level = <0xc9e>;
				qcom,mdss-dsi-bl-max-level = <0xfff>;
				qcom,mdss-dsi-lane-1-state;
				qcom,mdss-dsi-stream = <0x00>;
				qcom,mdss-dsi-traffic-mode = "non_burst_sync_event";
				linux,phandle = <0x2f0>;
				qcom,mdss-dsi-t-clk-post = <0x03>;
				qcom,panel-ack-disabled;
				qcom,mdss-dsi-wr-mem-start = <0x2c>;

				qcom,mdss-dsi-display-timings {

					timing@0 {
						qcom,mdss-dsi-on-command = <0x29010000 0x2b0 0x3050100 0xa0001 0x150100 0xa0002 0x3a773901 0xa00 0x52a0000 0x4ff3901 0xa00 0x52b0000 0x59f1501 0xa00 0x2350039 0x100000a 0x34400 0x150100 0xa0002 0x51ff1501 0xa00 0x2532415 0x100000a 0x25500 0x5010000 0x78000111 0x5010000 0x10000129>;
						qcom,mdss-dsi-off-command = [05 01 00 00 32 00 02 28 00 05 01 00 00 78 00 02 10 00];
						qcom,mdss-dsi-v-bottom-border = <0x00>;
						qcom,mdss-dsi-on-command-state = "dsi_lp_mode";
						qcom,mdss-dsi-h-back-porch = <0x64>;
						qcom,mdss-dsi-v-back-porch = <0x64>;
						qcom,mdss-dsi-panel-width = <0x5a0>;
						qcom,mdss-dsi-h-sync-skew = <0x00>;
						qcom,mdss-dsi-h-front-porch = <0x78>;
						qcom,mdss-dsi-v-front-porch = <0x64>;
						qcom,mdss-dsc-bit-per-component = <0x08>;
						qcom,mdss-dsc-slice-per-pkt = <0x01>;
						qcom,mdss-dsi-v-top-border = <0x00>;
						qcom,mdss-dsi-panel-height = <0xa00>;
						qcom,mdss-dsc-block-prediction-enable;
						qcom,mdss-dsi-h-left-border = <0x00>;
						qcom,mdss-dsi-off-command-state = "dsi_hs_mode";
						qcom,mdss-dsi-panel-framerate = <0x3c>;
						qcom,mdss-dsi-h-pulse-width = <0x28>;
						qcom,mdss-dsi-v-pulse-width = <0x28>;
						qcom,mdss-dsc-slice-width = <0x2d0>;
						qcom,mdss-dsc-slice-height = <0x28>;
						qcom,mdss-dsi-h-right-border = <0x00>;
						qcom,compression-mode = "dsc";
						qcom,mdss-dsc-bit-per-pixel = <0x08>;
						qcom,mdss-dsi-panel-timings = <0x210909 0x24230808 0x8030400>;
					};

					timing@2 {
						qcom,mdss-dsi-on-command = <0x29010000 0x2b0 0x3050100 0xa0001 0x150100 0xa0002 0x3a773901 0xa00 0x52a0000 0x4ff3901 0xa00 0x52b0000 0x59f1501 0xa00 0x2350039 0x100000a 0x34400 0x150100 0xa0002 0x51ff1501 0xa00 0x2532415 0x100000a 0x25500 0x5010000 0x78000111 0x5010000 0x10000129>;
						qcom,mdss-dsi-off-command = [05 01 00 00 32 00 02 28 00 05 01 00 00 78 00 02 10 00];
						qcom,mdss-dsi-v-bottom-border = <0x00>;
						qcom,mdss-dsi-on-command-state = "dsi_lp_mode";
						qcom,mdss-dsi-h-back-porch = <0x348>;
						qcom,mdss-dsi-v-back-porch = <0x64>;
						qcom,mdss-dsi-panel-width = <0x2d0>;
						qcom,mdss-dsi-h-sync-skew = <0x00>;
						qcom,mdss-dsi-h-front-porch = <0x64>;
						qcom,mdss-dsi-v-front-porch = <0x564>;
						qcom,mdss-dsc-bit-per-component = <0x08>;
						qcom,mdss-dsc-slice-per-pkt = <0x01>;
						qcom,mdss-dsi-v-top-border = <0x00>;
						qcom,mdss-dsi-panel-height = <0x500>;
						qcom,mdss-dsc-block-prediction-enable;
						qcom,mdss-dsi-h-left-border = <0x00>;
						qcom,mdss-dsi-off-command-state = "dsi_hs_mode";
						qcom,mdss-dsi-panel-framerate = <0x3c>;
						qcom,mdss-dsi-h-pulse-width = <0x28>;
						qcom,mdss-dsi-v-pulse-width = <0x28>;
						qcom,mdss-dsc-slice-width = <0x168>;
						qcom,mdss-dsc-slice-height = <0x28>;
						qcom,mdss-dsi-h-right-border = <0x00>;
						qcom,compression-mode = "dsc";
						qcom,mdss-dsc-bit-per-pixel = <0x08>;
						qcom,mdss-dsi-panel-timings = <0x210909 0x24230808 0x8030400>;
					};

					timing@1 {
						qcom,mdss-dsi-on-command = <0x29010000 0x2b0 0x3050100 0xa0001 0x150100 0xa0002 0x3a773901 0xa00 0x52a0000 0x4ff3901 0xa00 0x52b0000 0x59f1501 0xa00 0x2350039 0x100000a 0x34400 0x150100 0xa0002 0x51ff1501 0xa00 0x2532415 0x100000a 0x25500 0x5010000 0x78000111 0x5010000 0x10000129>;
						qcom,mdss-dsi-off-command = [05 01 00 00 32 00 02 28 00 05 01 00 00 78 00 02 10 00];
						qcom,mdss-dsi-v-bottom-border = <0x00>;
						qcom,mdss-dsi-on-command-state = "dsi_lp_mode";
						qcom,mdss-dsi-h-back-porch = <0x1cc>;
						qcom,mdss-dsi-v-back-porch = <0x64>;
						qcom,mdss-dsi-panel-width = <0x438>;
						qcom,mdss-dsi-h-sync-skew = <0x00>;
						qcom,mdss-dsi-h-front-porch = <0x78>;
						qcom,mdss-dsi-v-front-porch = <0x2e4>;
						qcom,mdss-dsc-bit-per-component = <0x08>;
						qcom,mdss-dsc-slice-per-pkt = <0x01>;
						qcom,mdss-dsi-v-top-border = <0x00>;
						qcom,mdss-dsi-panel-height = <0x780>;
						qcom,mdss-dsc-block-prediction-enable;
						qcom,mdss-dsi-h-left-border = <0x00>;
						qcom,mdss-dsi-off-command-state = "dsi_hs_mode";
						qcom,mdss-dsi-panel-framerate = <0x3c>;
						qcom,mdss-dsi-h-pulse-width = <0x28>;
						qcom,mdss-dsi-v-pulse-width = <0x28>;
						qcom,mdss-dsc-slice-width = <0x21c>;
						qcom,mdss-dsc-slice-height = <0x28>;
						qcom,mdss-dsi-h-right-border = <0x00>;
						qcom,compression-mode = "dsc";
						qcom,mdss-dsc-bit-per-pixel = <0x08>;
						qcom,mdss-dsi-panel-timings = <0x210909 0x24230808 0x8030400>;
					};
				};
			};

			qcom,mdss_dsi_truly_1080p_video {
				qcom,esd-check-enabled;
				qcom,mdss-dsi-bllp-power-mode;
				qcom,mdss-dsi-on-command = [15 01 00 00 00 00 02 35 00 15 01 00 00 00 00 02 51 ff 15 01 00 00 00 00 02 53 2c 15 01 00 00 00 00 02 55 00 05 01 00 00 78 00 02 11 00 23 01 00 00 00 00 02 b0 00 29 01 00 00 00 00 07 b3 14 00 00 00 00 00 29 01 00 00 00 00 03 b6 3a d3 29 01 00 00 00 00 03 c0 00 00 29 01 00 00 00 00 23 c1 84 60 10 eb ff 6f ce ff ff 17 02 58 73 ae b1 20 c6 ff ff 1f f3 ff 5f 10 10 10 10 00 02 01 22 22 00 01 29 01 00 00 00 00 08 c2 31 f7 80 06 08 00 00 29 01 00 00 00 00 17 c4 70 00 00 00 00 04 00 00 00 0c 06 00 00 00 00 00 04 00 00 00 0c 06 29 01 00 00 00 00 29 c6 00 69 00 69 00 69 00 00 00 00 00 69 00 69 00 69 10 19 07 00 01 00 69 00 69 00 69 00 00 00 00 00 69 00 69 00 69 10 19 07 29 01 00 00 00 00 0a cb 31 fc 3f 8c 00 00 00 00 c0 23 01 00 00 00 00 02 cc 0b 29 01 00 00 00 00 0b d0 11 81 bb 1e 1e 4c 19 19 0c 00 29 01 00 00 00 00 1a d3 1b 33 bb bb b3 33 33 33 00 01 00 a0 d8 a0 0d 4e 4e 33 3b 22 72 07 3d bf 33 29 01 00 00 00 00 08 d5 06 00 00 01 51 01 32 29 01 00 00 00 00 1f c7 01 0a 11 18 26 33 3e 50 38 42 52 60 67 6e 77 01 0a 11 18 26 33 3e 50 38 42 52 60 67 6e 77 29 01 00 00 14 00 14 c8 01 00 00 00 00 fc 00 00 00 00 00 fc 00 00 00 00 00 fc 00 05 01 00 00 14 00 02 29 00];
				qcom,mdss-dsi-off-command = [05 01 00 00 14 00 02 28 00 05 01 00 00 78 00 02 10 00];
				qcom,mdss-dsi-bl-pmic-pwm-frequency = <0x64>;
				qcom,mdss-dsi-v-bottom-border = <0x00>;
				qcom,mdss-dsi-t-clk-pre = <0x2d>;
				qcom,mdss-dsi-bl-min-level = <0x01>;
				qcom,mdss-dsi-on-command-state = "dsi_lp_mode";
				qcom,mdss-dsi-h-back-porch = <0x40>;
				qcom,mdss-dsi-v-back-porch = <0x10>;
				qcom,mdss-dsi-panel-name = "truly 1080p video mode dsi panel";
				qcom,mdss-dsi-lane-2-state;
				qcom,mdss-dsi-bllp-eof-power-mode;
				qcom,mdss-dsi-panel-status-check-mode = "reg_read";
				qcom,mdss-dsi-panel-width = <0x438>;
				qcom,mdss-dsi-h-sync-skew = <0x00>;
				qcom,mdss-dsi-reset-sequence = <0x01 0x0a 0x00 0x0a 0x01 0x0a>;
				qcom,mdss-dsi-panel-max-error-count = <0x03>;
				qcom,mdss-dsi-pan-enable-dynamic-fps;
				qcom,mdss-dsi-tx-eot-append;
				qcom,mdss-dsi-h-front-porch = <0x60>;
				qcom,mdss-dsi-v-front-porch = <0x04>;
				qcom,mdss-dsi-dma-trigger = "trigger_sw";
				qcom,mdss-dsi-v-top-border = <0x00>;
				qcom,mdss-dsi-pan-fps-update = "dfps_immediate_porch_mode_vfp";
				qcom,mdss-dsi-panel-status-command = <0x6010001 0x10a>;
				qcom,mdss-dsi-panel-height = <0x780>;
				qcom,mdss-dsi-h-sync-pulse = <0x00>;
				qcom,mdss-dsi-virtual-channel-id = <0x00>;
				qcom,mdss-dsi-lane-0-state;
				qcom,mdss-dsi-panel-timings-phy-v2 = <0x231e0809 0x50304a0 0x231e0809 0x50304a0 0x231e0809 0x50304a0 0x231e0809 0x50304a0 0x231a0809 0x50304a0>;
				qcom,mdss-dsi-underflow-color = <0xff>;
				qcom,mdss-dsi-panel-status-read-length = <0x01>;
				qcom,mdss-dsi-lane-3-state;
				qcom,mdss-dsi-h-left-border = <0x00>;
				qcom,mdss-dsi-border-color = <0x00>;
				qcom,mdss-dsi-panel-status-command-state = "dsi_hs_mode";
				qcom,mdss-dsi-mdp-trigger = "none";
				phandle = <0x2e9>;
				qcom,mdss-dsi-bpp = <0x18>;
				qcom,mdss-dsi-bl-pmic-bank-select = <0x00>;
				qcom,mdss-dsi-panel-type = "dsi_video_mode";
				qcom,mdss-dsi-panel-status-value = <0x1c>;
				qcom,mdss-dsi-off-command-state = "dsi_lp_mode";
				qcom,mdss-dsi-panel-framerate = <0x3c>;
				qcom,mdss-dsi-bl-max-level = <0xfff>;
				qcom,mdss-dsi-lane-1-state;
				qcom,mdss-dsi-h-pulse-width = <0x10>;
				qcom,mdss-dsi-v-pulse-width = <0x01>;
				qcom,panel-supply-entries = <0x2e8>;
				qcom,mdss-dsi-bl-pmic-control-type = "bl_ctrl_pwm";
				qcom,mdss-dsi-pwm-gpio = <0x14d 0x08 0x00>;
				qcom,mdss-dsi-stream = <0x00>;
				qcom,mdss-dsi-traffic-mode = "burst_mode";
				linux,phandle = <0x2e9>;
				qcom,mdss-dsi-panel-on-check-value = <0x1c>;
				qcom,mdss-dsi-h-right-border = <0x00>;
				qcom,mdss-dsi-t-clk-post = <0x02>;
				qcom,mdss-dsi-post-init-delay = <0x01>;
				qcom,mdss-dsi-panel-timings = <0xe6382600 0x686e2a3c 0x44030400>;
			};

			qcom,mdss_dsi_sim_video {
				qcom,mdss-dsi-bllp-power-mode;
				qcom,mdss-dsi-t-clk-pre = <0x1b>;
				qcom,mdss-dsi-panel-name = "Simulator video mode dsi panel";
				qcom,mdss-dsi-lane-2-state;
				qcom,mdss-dsi-bllp-eof-power-mode;
				qcom,mdss-dsi-reset-sequence = <0x01 0x00 0x00 0x00 0x01 0x00>;
				qcom,mdss-dsi-panel-hdr-enabled;
				qcom,mdss-dsi-dma-trigger = "trigger_sw";
				qcom,mdss-dsi-virtual-channel-id = <0x00>;
				qcom,mdss-dsi-panel-peak-brightness = <0x401640>;
				qcom,mdss-dsi-lane-0-state;
				qcom,mdss-dsi-underflow-color = <0xff>;
				qcom,mdss-dsi-lane-3-state;
				qcom,mdss-dsi-border-color = <0x00>;
				qcom,mdss-dsi-mdp-trigger = "none";
				phandle = <0x2eb>;
				qcom,mdss-dsi-bpp = <0x18>;
				qcom,mdss-dsi-panel-type = "dsi_video_mode";
				qcom,mdss-dsi-panel-hdr-color-primaries = <0x38a4 0x3c8c 0x7d00 0x4268 0x3c8c 0x7530 0x1f40 0xbb8>;
				qcom,mdss-dsi-panel-blackness-level = <0xc9e>;
				qcom,mdss-dsi-lane-1-state;
				qcom,mdss-dsi-stream = <0x00>;
				qcom,mdss-dsi-traffic-mode = "non_burst_sync_event";
				linux,phandle = <0x2eb>;
				qcom,mdss-dsi-t-clk-post = <0x04>;
				qcom,panel-ack-disabled;

				qcom,mdss-dsi-display-timings {

					timing@0 {
						qcom,mdss-dsi-on-command = [32 01 00 00 00 00 02 00 00];
						qcom,mdss-dsi-off-command = [22 01 00 00 00 00 02 00 00];
						qcom,mdss-dsi-v-bottom-border = <0x00>;
						qcom,mdss-dsi-on-command-state = "dsi_lp_mode";
						qcom,mdss-dsi-h-back-porch = <0x08>;
						qcom,mdss-dsi-v-back-porch = <0x06>;
						qcom,mdss-dsi-panel-width = <0x280>;
						qcom,mdss-dsi-h-sync-skew = <0x00>;
						qcom,mdss-dsi-h-front-porch = <0x08>;
						qcom,mdss-dsi-v-front-porch = <0x06>;
						qcom,mdss-dsi-v-top-border = <0x00>;
						qcom,mdss-dsi-panel-height = <0x1e0>;
						qcom,mdss-dsi-h-sync-pulse = <0x00>;
						qcom,mdss-dsi-h-left-border = <0x00>;
						qcom,mdss-dsi-off-command-state = "dsi_lp_mode";
						qcom,mdss-dsi-panel-framerate = <0x3c>;
						qcom,mdss-dsi-h-pulse-width = <0x08>;
						qcom,mdss-dsi-v-pulse-width = <0x02>;
						qcom,mdss-dsi-h-right-border = <0x00>;
						qcom,mdss-dsi-panel-timings = <0x00 0x00 0x00>;
					};
				};
			};

			mdss_fb1: qcom,mdss_fb_wfd {
				compatible = "qcom,mdss-fb";
				phandle = <0xb8>;
				linux,phandle = <0xb8>;
				cell-index = <0x01>;
			};

			smmu_mdp_sec: qcom,smmu_mdp_sec_cb {
				compatible = "qcom,smmu_mdp_sec";
				phandle = <0x250>;
				iommus = <0xa5 0xc01 0x00>;
				linux,phandle = <0x250>;
			};

			mdss_fb0: qcom,mdss_fb_primary {
				compatible = "qcom,mdss-fb";
				phandle = <0xb0>;
				linux,phandle = <0xb0>;
				cell-index = <0x00>;

				qcom,cont-splash-memory {
					linux,contiguous-region = <0xad>;
				};
			};

			qcom,mdss_dsi_adv7533_1080p {
				qcom,mdss-dsi-bllp-power-mode;
				qcom,mdss-dsi-on-command = [05 01 00 00 c8 00 02 11 00 05 01 00 00 0a 00 02 29 00];
				qcom,mdss-dsi-off-command = [05 01 00 00 00 00 02 28 00 05 01 00 00 00 00 02 10 00];
				qcom,mdss-dsi-v-bottom-border = <0x00>;
				qcom,mdss-dsi-t-clk-pre = <0x2b>;
				qcom,mdss-dsi-bl-min-level = <0x01>;
				qcom,mdss-dsi-on-command-state = "dsi_lp_mode";
				qcom,mdss-dsi-h-back-porch = <0x94>;
				qcom,mdss-dsi-v-back-porch = <0x24>;
				qcom,mdss-dsi-panel-name = "dsi_adv7533_1080p";
				qcom,mdss-dsi-lane-2-state;
				qcom,mdss-dsi-bllp-eof-power-mode;
				qcom,mdss-dsi-panel-width = <0x780>;
				qcom,mdss-dsi-h-sync-skew = <0x00>;
				qcom,mdss-dsi-reset-sequence = <0x01 0x14 0x00 0x01 0x01 0x14>;
				qcom,mdss-dsi-h-front-porch = <0x58>;
				qcom,mdss-dsi-v-front-porch = <0x04>;
				qcom,mdss-dsi-dma-trigger = "trigger_sw";
				qcom,mdss-dsi-panel-destination = "display_1";
				qcom,mdss-dsi-v-top-border = <0x00>;
				qcom,mdss-dsi-panel-height = <0x438>;
				qcom,mdss-dsi-h-sync-pulse = <0x01>;
				qcom,mdss-dsi-virtual-channel-id = <0x00>;
				qcom,mdss-dsi-lane-0-state;
				qcom,mdss-dsi-panel-timings-phy-v2 = <0x241f0809 0x50304a0 0x241f0809 0x50304a0 0x241f0809 0x50304a0 0x241f0809 0x50304a0 0x241b0809 0x50304a0>;
				qcom,mdss-dsi-underflow-color = <0xff>;
				qcom,mdss-dsi-lane-3-state;
				qcom,mdss-dsi-h-left-border = <0x00>;
				qcom,mdss-dsi-border-color = <0x00>;
				qcom,mdss-pan-physical-width-dimension = <0xa0>;
				qcom,mdss-dsi-mdp-trigger = "none";
				label = "adv7533 1080p video mode dsi panel";
				phandle = <0x2ea>;
				qcom,mdss-dsi-bpp = <0x18>;
				qcom,mdss-dsi-panel-type = "dsi_video_mode";
				qcom,mdss-pan-physical-height-dimension = <0x5a>;
				qcom,mdss-dsi-off-command-state = "dsi_hs_mode";
				qcom,mdss-dsi-panel-framerate = <0x3c>;
				qcom,dba-panel;
				qcom,mdss-dsi-bl-max-level = <0xfff>;
				qcom,mdss-dsi-lane-1-state;
				qcom,mdss-dsi-h-pulse-width = <0x2c>;
				qcom,mdss-dsi-v-pulse-width = <0x05>;
				qcom,mdss-dsi-force-clock-lane-hs;
				qcom,mdss-dsi-stream = <0x00>;
				qcom,mdss-dsi-traffic-mode = "non_burst_sync_pulse";
				linux,phandle = <0x2ea>;
				qcom,mdss-dsi-always-on;
				qcom,mdss-dsi-h-right-border = <0x00>;
				qcom,mdss-dsi-t-clk-post = <0x02>;
				qcom,mdss-dsi-panel-controller = <0x252>;
				qcom,bridge-name = "adv7533";
				qcom,mdss-dsi-panel-timings = <0xe6382600 0x686c2a3a 0x2c030400>;
			};

			qcom,mdss-pp-offsets {
				qcom,mdss-sspp-dma-pcc-off = <0x380>;
				qcom,mdss-lm-pgc-off = <0x3c0>;
				qcom,mdss-dspp-pcc-off = <0x1700>;
				qcom,mdss-sspp-mdss-igc-lut-off = <0x2000>;
				qcom,mdss-sspp-vig-pcc-off = <0x1780>;
				qcom,mdss-dspp-pgc-off = <0x17c0>;
				qcom,mdss-sspp-rgb-pcc-off = <0x380>;
			};

			qcom,mdss_dsi_lt8912_480p_video {
				qcom,mdss-dsi-bllp-power-mode;
				qcom,mdss-dsi-on-command = [05 01 00 00 a0 00 02 11 00 05 01 00 00 a0 00 02 29 00];
				qcom,mdss-dsi-off-command = [05 01 00 00 78 00 02 28 00 05 01 00 00 78 00 02 10 00];
				qcom,mdss-dsi-v-bottom-border = <0x00>;
				qcom,mdss-dsi-color-order = "rgb_swap_rgb";
				qcom,mdss-dsi-t-clk-pre = <0x2b>;
				qcom,mdss-dsi-on-command-state = "dsi_lp_mode";
				qcom,mdss-dsi-h-back-porch = <0x30>;
				qcom,mdss-dsi-v-back-porch = <0x20>;
				qcom,mdss-dsi-panel-name = "lt8912 480p video mode dsi panel";
				qcom,mdss-dsi-bllp-eof-power-mode;
				qcom,mdss-dsi-panel-width = <0x280>;
				qcom,mdss-dsi-h-sync-skew = <0x00>;
				qcom,mdss-dsi-reset-sequence = <0x01 0x14 0x00 0x02 0x01 0x14>;
				qcom,mdss-dsi-h-front-porch = <0x10>;
				qcom,mdss-dsi-v-front-porch = <0x0f>;
				qcom,mdss-dsi-dma-trigger = "trigger_sw";
				qcom,mdss-dsi-panel-destination = "display_1";
				qcom,mdss-dsi-v-top-border = <0x00>;
				qcom,mdss-dsi-panel-height = <0x1e0>;
				qcom,mdss-dsi-h-sync-pulse = <0x00>;
				qcom,mdss-dsi-virtual-channel-id = <0x00>;
				qcom,mdss-dsi-lane-0-state;
				qcom,mdss-dsi-panel-timings-phy-v2 = <0x1d1a0305 0x10304a0 0x1d1a0305 0x10304a0 0x1d0a0304 0x10304a0>;
				qcom,mdss-dsi-underflow-color = <0xff>;
				qcom,mdss-dsi-h-left-border = <0x00>;
				qcom,mdss-dsi-border-color = <0x00>;
				qcom,mdss-dsi-mdp-trigger = "none";
				phandle = <0x2f7>;
				qcom,mdss-dsi-bpp = <0x18>;
				qcom,mdss-dsi-panel-type = "dsi_video_mode";
				qcom,mdss-dsi-lane-map = "lane_map_0123";
				qcom,mdss-dsi-off-command-state = "dsi_lp_mode";
				qcom,mdss-dsi-panel-framerate = <0x3c>;
				qcom,mdss-dsi-lane-1-state;
				qcom,mdss-dsi-h-pulse-width = <0x60>;
				qcom,mdss-dsi-v-pulse-width = <0x02>;
				qcom,mdss-dsi-force-clock-lane-hs;
				qcom,mdss-dsi-stream = <0x00>;
				qcom,mdss-dsi-traffic-mode = "non_burst_sync_event";
				linux,phandle = <0x2f7>;
				qcom,mdss-dsi-h-right-border = <0x00>;
				qcom,mdss-dsi-t-clk-post = <0x02>;
				qcom,mdss-dsi-post-init-delay = <0x01>;
				qcom,mdss-dsi-panel-timings = <0x65120c00 0x34381016 0xf030400>;
			};

			qcom,mdss_dsi_nt36672_csot_fhdp_video {
				qcom,esd-check-enabled;
				qcom,mdss-dsi-bllp-power-mode;
				qcom,mdss-dsi-on-command = [15 01 00 00 00 00 02 ff 20 15 01 00 00 00 00 02 fb 01 15 01 00 00 00 00 02 06 9e 15 01 00 00 00 00 02 07 94 15 01 00 00 00 00 02 0e 35 15 01 00 00 00 00 02 0f 24 15 01 00 00 00 00 02 68 03 15 01 00 00 00 00 02 6d 66 15 01 00 00 00 00 02 69 99 15 01 00 00 00 00 02 95 eb 15 01 00 00 00 00 02 96 eb 15 01 00 00 00 00 02 ff 20 15 01 00 00 00 00 02 fb 01 39 01 00 00 00 00 11 b0 00 00 00 16 00 39 00 55 00 6e 00 85 00 99 00 ac 39 01 00 00 00 00 11 b1 00 bd 00 f7 01 21 01 65 01 93 01 e0 02 18 02 1a 39 01 00 00 00 00 11 b2 02 53 02 94 02 c3 02 f5 03 15 03 4c 03 56 03 64 39 01 00 00 00 00 0d b3 03 74 03 86 03 9c 03 b6 03 ce 03 ff 39 01 00 00 00 00 11 b4 00 00 00 16 00 39 00 55 00 6e 00 85 00 99 00 ac 39 01 00 00 00 00 11 b5 00 bd 00 f7 01 21 01 65 01 93 01 e0 02 18 02 1a 39 01 00 00 00 00 11 b6 02 53 02 94 02 c3 02 f5 03 15 03 4c 03 56 03 64 39 01 00 00 00 00 0d b7 03 74 03 86 03 9c 03 b6 03 ce 03 ff 39 01 00 00 00 00 11 b8 00 00 00 16 00 39 00 55 00 6e 00 85 00 99 00 ac 39 01 00 00 00 00 11 b9 00 bd 00 f7 01 21 01 65 01 93 01 e0 02 18 02 1a 39 01 00 00 00 00 11 ba 02 53 02 94 02 c3 02 f5 03 15 03 4c 03 56 03 64 39 01 00 00 00 00 0d bb 03 74 03 86 03 9c 03 b6 03 ce 03 ff 15 01 00 00 00 00 02 ff 21 15 01 00 00 00 00 02 fb 01 39 01 00 00 00 00 11 b0 00 00 00 16 00 39 00 55 00 6e 00 85 00 99 00 ac 39 01 00 00 00 00 11 b1 00 bd 00 f7 01 21 01 65 01 93 01 e0 02 18 02 1a 39 01 00 00 00 00 11 b2 02 53 02 94 02 c3 02 f5 03 15 03 4c 03 56 03 64 39 01 00 00 00 00 0d b3 03 74 03 86 03 9c 03 b6 03 ce 03 ff 39 01 00 00 00 00 11 b4 00 00 00 16 00 39 00 55 00 6e 00 85 00 99 00 ac 39 01 00 00 00 00 11 b5 00 bd 00 f7 01 21 01 65 01 93 01 e0 02 18 02 1a 39 01 00 00 00 00 11 b6 02 53 02 94 02 c3 02 f5 03 15 03 4c 03 56 03 64 39 01 00 00 00 00 0d b7 03 74 03 86 03 9c 03 b6 03 ce 03 ff 39 01 00 00 00 00 11 b8 00 00 00 16 00 39 00 55 00 6e 00 85 00 99 00 ac 39 01 00 00 00 00 11 b9 00 bd 00 f7 01 21 01 65 01 93 01 e0 02 18 02 1a 39 01 00 00 00 00 11 ba 02 53 02 94 02 c3 02 f5 03 15 03 4c 03 56 03 64 39 01 00 00 00 00 0d bb 03 74 03 86 03 9c 03 b6 03 ce 03 ff 15 01 00 00 00 00 02 ff 24 15 01 00 00 00 00 02 fb 01 15 01 00 00 00 00 02 00 20 15 01 00 00 00 00 02 01 20 15 01 00 00 00 00 02 02 20 15 01 00 00 00 00 02 03 01 15 01 00 00 00 00 02 04 0b 15 01 00 00 00 00 02 05 0c 15 01 00 00 00 00 02 06 a9 15 01 00 00 00 00 02 07 06 15 01 00 00 00 00 02 08 04 15 01 00 00 00 00 02 09 20 15 01 00 00 00 00 02 0a 0f 15 01 00 00 00 00 02 0b 20 15 01 00 00 00 00 02 0c 20 15 01 00 00 00 00 02 0d 20 15 01 00 00 00 00 02 0e 20 15 01 00 00 00 00 02 0f 17 15 01 00 00 00 00 02 10 15 15 01 00 00 00 00 02 11 13 15 01 00 00 00 00 02 12 00 15 01 00 00 00 00 02 13 00 15 01 00 00 00 00 02 14 20 15 01 00 00 00 00 02 15 01 15 01 00 00 00 00 02 16 0b 15 01 00 00 00 00 02 17 0c 15 01 00 00 00 00 02 18 a9 15 01 00 00 00 00 02 19 05 15 01 00 00 00 00 02 1a 03 15 01 00 00 00 00 02 1b 20 15 01 00 00 00 00 02 1c 0f 15 01 00 00 00 00 02 1d 20 15 01 00 00 00 00 02 1e 20 15 01 00 00 00 00 02 1f 20 15 01 00 00 00 00 02 20 20 15 01 00 00 00 00 02 21 17 15 01 00 00 00 00 02 22 15 15 01 00 00 00 00 02 23 13 15 01 00 00 00 00 02 2f 04 15 01 00 00 00 00 02 30 08 15 01 00 00 00 00 02 31 04 15 01 00 00 00 00 02 32 08 15 01 00 00 00 00 02 33 02 15 01 00 00 00 00 02 34 02 15 01 00 00 00 00 02 35 00 15 01 00 00 00 00 02 37 02 15 01 00 00 00 00 02 38 72 15 01 00 00 00 00 02 39 72 15 01 00 00 00 00 02 3b 40 15 01 00 00 00 00 02 3f 72 15 01 00 00 00 00 02 60 10 15 01 00 00 00 00 02 61 00 15 01 00 00 00 00 02 68 83 15 01 00 00 00 00 02 78 00 15 01 00 00 00 00 02 79 00 15 01 00 00 00 00 02 7a 08 15 01 00 00 00 00 02 7b 9c 15 01 00 00 00 00 02 7d 06 15 01 00 00 00 00 02 7e 02 15 01 00 00 00 00 02 80 45 15 01 00 00 00 00 02 81 06 15 01 00 00 00 00 02 8e f0 15 01 00 00 00 00 02 90 00 15 01 00 00 00 00 02 92 76 15 01 00 00 00 00 02 93 0a 15 01 00 00 00 00 02 94 0a 15 01 00 00 00 00 02 99 33 15 01 00 00 00 00 02 9b ff 15 01 00 00 00 00 02 b3 00 15 01 00 00 00 00 02 b4 04 15 01 00 00 00 00 02 b5 04 15 01 00 00 00 00 02 dc 00 15 01 00 00 00 00 02 dd 01 15 01 00 00 00 00 02 de 00 15 01 00 00 00 00 02 df 00 15 01 00 00 00 00 02 e0 75 15 01 00 00 00 00 02 e9 08 15 01 00 00 00 00 02 ed 40 15 01 00 00 00 00 02 ff 25 15 01 00 00 00 00 02 fb 01 15 01 00 00 00 00 02 0a 81 15 01 00 00 00 00 02 0b d7 15 01 00 00 00 00 02 0c 01 15 01 00 00 00 00 02 17 82 15 01 00 00 00 00 02 21 1c 15 01 00 00 00 00 02 22 1c 15 01 00 00 00 00 02 24 76 15 01 00 00 00 00 02 25 76 15 01 00 00 00 00 02 5c 25 15 01 00 00 00 00 02 5d 80 15 01 00 00 00 00 02 5e 80 15 01 00 00 00 00 02 5f 22 15 01 00 00 00 00 02 65 00 15 01 00 00 00 00 02 69 60 15 01 00 00 00 00 02 6b 00 15 01 00 00 00 00 02 71 2d 15 01 00 00 00 00 02 80 00 15 01 00 00 00 00 02 84 68 15 01 00 00 00 00 02 8d 04 15 01 00 00 00 00 02 d7 00 15 01 00 00 00 00 02 d8 00 15 01 00 00 00 00 02 d9 00 15 01 00 00 00 00 02 da 00 15 01 00 00 00 00 02 db 00 15 01 00 00 00 00 02 dc 00 15 01 00 00 00 00 02 ff 26 15 01 00 00 00 00 02 fb 01 15 01 00 00 00 00 02 06 c8 15 01 00 00 00 00 02 12 5a 15 01 00 00 00 00 02 19 0a 15 01 00 00 00 00 02 1a 97 15 01 00 00 00 00 02 1d 0a 15 01 00 00 00 00 02 1e 1e 15 01 00 00 00 00 02 99 20 15 01 00 00 00 00 02 ff 27 15 01 00 00 00 00 02 fb 01 15 01 00 00 00 00 02 13 0e 15 01 00 00 00 00 02 16 b0 15 01 00 00 00 00 02 17 d0 15 01 00 00 00 00 02 ff 10 15 01 00 00 00 00 02 fb 01 15 01 00 00 00 00 02 51 ff 15 01 00 00 00 00 02 53 24 15 01 00 00 00 00 02 55 00 05 01 00 00 78 00 02 11 00 15 01 00 00 00 00 02 35 00 05 01 00 00 28 00 02 29 00];
				qcom,mdss-dsi-off-command = [15 01 00 00 00 00 02 ff 10 15 01 00 00 00 00 02 fb 01 05 01 00 00 14 00 02 28 00 05 01 00 00 3c 00 02 10 00 15 01 00 00 00 00 02 4f 01];
				qcom,mdss-dsi-bl-pmic-pwm-frequency = <0x1f4>;
				qcom,mdss-dsi-v-bottom-border = <0x00>;
				qcom,mdss-dsi-color-order = "rgb_swap_rgb";
				qcom,mdss-dsi-t-clk-pre = <0x30>;
				qcom,mdss-dsi-bl-min-level = <0x01>;
				qcom,mdss-dsi-on-command-state = "dsi_lp_mode";
				qcom,mdss-dsi-h-back-porch = <0x27>;
				qcom,mdss-dsi-v-back-porch = <0x05>;
				qcom,mdss-dsi-panel-name = "nt36672 csot fhdp video mode dsi panel";
				qcom,mdss-dsi-lane-2-state;
				qcom,mdss-dsi-lp11-init;
				qcom,mdss-dsi-bllp-eof-power-mode;
				qcom,mdss-dsi-panel-status-check-mode = "reg_read";
				qcom,mdss-dsi-panel-width = <0x438>;
				qcom,mdss-dsi-h-sync-skew = <0x00>;
				qcom,mdss-dsi-reset-sequence = <0x01 0x05 0x00 0x05 0x01 0x0a>;
				qcom,mdss-dsi-tx-eot-append;
				qcom,mdss-dsi-h-front-porch = <0x28>;
				qcom,mdss-dsi-v-front-porch = <0x0e>;
				qcom,mdss-dsi-dma-trigger = "trigger_sw";
				qcom,mdss-dsi-panel-destination = "display_1";
				qcom,mdss-dsi-v-top-border = <0x00>;
				qcom,mdss-dsi-panel-status-command = <0x6010001 0x10a>;
				qcom,mdss-dsi-panel-height = <0x870>;
				qcom,mdss-dsi-h-sync-pulse = <0x01>;
				qcom,mdss-dsi-virtual-channel-id = <0x00>;
				qcom,mdss-dsi-lane-0-state;
				qcom,mdss-dsi-panel-timings-phy-v2 = <0x241f0809 0x50304a0 0x241f0809 0x50304a0 0x241f0809 0x50304a0 0x241f0809 0x50304a0 0x241b0809 0x50304a0>;
				qcom,mdss-dsi-underflow-color = <0xff>;
				qcom,mdss-dsi-panel-status-read-length = <0x01>;
				qcom,mdss-dsi-lane-3-state;
				qcom,mdss-dsi-h-left-border = <0x00>;
				qcom,mdss-dsi-border-color = <0x00>;
				qcom,mdss-pan-physical-width-dimension = <0x44>;
				qcom,mdss-dsi-panel-status-command-state = "dsi_lp_mode";
				qcom,mdss-dsi-mdp-trigger = "none";
				phandle = <0x2ec>;
				qcom,mdss-dsi-bpp = <0x18>;
				qcom,mdss-dsi-bl-pmic-bank-select = <0x00>;
				qcom,mdss-dsi-panel-type = "dsi_video_mode";
				qcom,mdss-dsi-lane-map = "lane_map_0123";
				qcom,mdss-dsi-panel-status-value = <0x9c>;
				qcom,mdss-pan-physical-height-dimension = <0x88>;
				qcom,mdss-dsi-off-command-state = "dsi_lp_mode";
				qcom,mdss-dsi-panel-framerate = <0x3c>;
				qcom,mdss-dsi-bl-max-level = <0xff>;
				qcom,mdss-dsi-lane-1-state;
				qcom,mdss-dsi-h-pulse-width = <0x01>;
				qcom,mdss-dsi-v-pulse-width = <0x01>;
				qcom,panel-supply-entries = <0x2e8>;
				qcom,mdss-dsi-bl-pmic-control-type = "bl_ctrl_pwm";
				qcom,mdss-dsi-pwm-gpio = <0x14d 0x08 0x00>;
				qcom,mdss-dsi-stream = <0x00>;
				qcom,mdss-dsi-traffic-mode = "burst_mode";
				linux,phandle = <0x2ec>;
				qcom,mdss-dsi-h-right-border = <0x00>;
				qcom,mdss-dsi-t-clk-post = <0x0d>;
				qcom,mdss-dsi-panel-controller = <0x252>;
				qcom,mdss-dsi-panel-timings = <0xfb382600 0x6a6c2c3c 0x2f030400>;
			};

			qcom,mdss_dsi_truly_1080p_cmd {
				qcom,esd-check-enabled;
				qcom,mdss-dsi-bllp-power-mode;
				qcom,mdss-dsi-on-command = [23 01 00 00 00 00 02 d6 01 15 01 00 00 00 00 02 35 00 15 01 00 00 00 00 02 51 ff 15 01 00 00 00 00 02 53 2c 15 01 00 00 00 00 02 55 00 05 01 00 00 78 00 02 11 00 23 01 00 00 00 00 02 b0 04 29 01 00 00 00 00 07 b3 04 00 00 00 00 00 29 01 00 00 00 00 03 b6 3a d3 29 01 00 00 00 00 03 c0 00 00 29 01 00 00 00 00 23 c1 84 60 10 eb ff 6f ce ff ff 17 02 58 73 ae b1 20 c6 ff ff 1f f3 ff 5f 10 10 10 10 00 02 01 22 22 00 01 29 01 00 00 00 00 08 c2 31 f7 80 06 08 00 00 29 01 00 00 00 00 17 c4 70 00 00 00 00 04 00 00 00 0c 06 00 00 00 00 00 04 00 00 00 0c 06 29 01 00 00 00 00 29 c6 78 69 00 69 00 69 00 00 00 00 00 69 00 69 00 69 10 19 07 00 78 00 69 00 69 00 69 00 00 00 00 00 69 00 69 00 69 10 19 07 29 01 00 00 00 00 0a cb 31 fc 3f 8c 00 00 00 00 c0 23 01 00 00 00 00 02 cc 0b 29 01 00 00 00 00 0b d0 11 81 bb 1e 1e 4c 19 19 0c 00 29 01 00 00 00 00 1a d3 1b 33 bb bb b3 33 33 33 00 01 00 a0 d8 a0 0d 4e 4e 33 3b 22 72 07 3d bf 33 29 01 00 00 00 00 08 d5 06 00 00 01 51 01 32 29 01 00 00 00 00 1f c7 01 0a 11 18 26 33 3e 50 38 42 52 60 67 6e 77 01 0a 11 18 26 33 3e 50 38 42 52 60 67 6e 77 29 01 00 00 14 00 14 c8 01 00 00 00 00 fc 00 00 00 00 00 fc 00 00 00 00 00 fc 00 05 01 00 00 14 00 02 29 00];
				qcom,mdss-dsi-off-command = [05 01 00 00 14 00 02 28 00 05 01 00 00 78 00 02 10 00];
				qcom,mdss-dsi-v-bottom-border = <0x00>;
				qcom,mdss-dsi-t-clk-pre = <0x2d>;
				qcom,mdss-dsi-bl-min-level = <0x01>;
				qcom,mdss-dsi-on-command-state = "dsi_lp_mode";
				qcom,mdss-dsi-h-back-porch = <0x40>;
				qcom,mdss-dsi-v-back-porch = <0x10>;
				qcom,mdss-dsi-panel-name = "truly 1080p cmd mode dsi panel";
				qcom,mdss-dsi-lane-2-state;
				qcom,mdss-dsi-bllp-eof-power-mode;
				qcom,mdss-dsi-panel-status-check-mode = "reg_read";
				qcom,mdss-dsi-panel-width = <0x438>;
				qcom,mdss-dsi-h-sync-skew = <0x00>;
				qcom,mdss-dsi-reset-sequence = <0x01 0x0a 0x00 0x0a 0x01 0x0a>;
				qcom,mdss-dsi-panel-max-error-count = <0x03>;
				qcom,mdss-dsi-te-check-enable;
				qcom,mdss-dsi-tx-eot-append;
				qcom,mdss-dsi-te-pin-select = <0x01>;
				qcom,mdss-dsi-te-using-te-pin;
				qcom,mdss-dsi-h-front-porch = <0x60>;
				qcom,partial-update-enabled;
				qcom,mdss-dsi-v-front-porch = <0x04>;
				qcom,mdss-dsi-dma-trigger = "trigger_sw";
				qcom,mdss-dsi-v-top-border = <0x00>;
				qcom,ulps-enabled;
				qcom,mdss-dsi-panel-status-command = <0x6010001 0x10a>;
				qcom,mdss-dsi-panel-height = <0x780>;
				qcom,mdss-dsi-te-dcs-command = <0x01>;
				qcom,mdss-dsi-h-sync-pulse = <0x00>;
				qcom,mdss-dsi-virtual-channel-id = <0x00>;
				qcom,mdss-dsi-lane-0-state;
				qcom,mdss-dsi-panel-timings-phy-v2 = <0x231e0809 0x50304a0 0x231e0809 0x50304a0 0x231e0809 0x50304a0 0x231e0809 0x50304a0 0x231a0809 0x50304a0>;
				qcom,mdss-dsi-underflow-color = <0xff>;
				qcom,mdss-dsi-panel-status-read-length = <0x01>;
				qcom,mdss-dsi-lane-3-state;
				qcom,mdss-dsi-h-left-border = <0x00>;
				qcom,mdss-dsi-border-color = <0x00>;
				qcom,mdss-dsi-panel-status-command-state = "dsi_hs_mode";
				qcom,mdss-dsi-mdp-trigger = "none";
				phandle = <0x2f2>;
				qcom,mdss-dsi-bpp = <0x18>;
				qcom,mdss-dsi-panel-type = "dsi_cmd_mode";
				qcom,mdss-dsi-panel-status-value = <0x1c>;
				qcom,panel-roi-alignment = <0x02 0x02 0x04 0x02 0x438 0x02>;
				qcom,mdss-dsi-off-command-state = "dsi_lp_mode";
				qcom,mdss-dsi-panel-framerate = <0x3c>;
				qcom,mdss-dsi-bl-max-level = <0xfff>;
				qcom,mdss-dsi-lane-1-state;
				qcom,mdss-dsi-h-pulse-width = <0x10>;
				qcom,mdss-dsi-v-pulse-width = <0x01>;
				qcom,panel-supply-entries = <0x2e8>;
				qcom,mdss-dsi-bl-pmic-control-type = "bl_ctrl_wled";
				qcom,mdss-dsi-stream = <0x00>;
				qcom,mdss-dsi-traffic-mode = "burst_mode";
				linux,phandle = <0x2f2>;
				qcom,mdss-dsi-panel-on-check-value = <0x1c>;
				qcom,mdss-dsi-h-right-border = <0x00>;
				qcom,mdss-dsi-t-clk-post = <0x02>;
				qcom,mdss-dsi-post-init-delay = <0x01>;
				qcom,mdss-dsi-panel-timings = <0xe6382600 0x686e2a3c 0x44030400>;
			};

			qcom,mdss_dsi_hx8399c_truly_video {
				qcom,esd-check-enabled;
				qcom,mdss-dsi-bllp-power-mode;
				qcom,mdss-dsi-on-command = [39 01 00 00 00 00 04 b9 ff 83 99 39 01 00 00 00 00 02 d2 88 39 01 00 00 00 00 0c b1 02 04 72 92 01 32 aa 11 11 52 57 39 01 00 00 00 00 10 b2 00 80 80 cc 05 07 5a 11 10 10 00 1e 70 03 d4 39 01 00 00 00 00 2d b4 00 ff 59 59 01 ab 00 00 09 00 03 05 00 28 03 0b 0d 21 03 02 00 0c a3 80 59 59 02 ab 00 00 09 00 03 05 00 28 03 0b 0d 02 00 0c a3 01 39 01 00 00 05 00 22 d3 00 0c 03 03 00 00 10 10 00 00 03 00 03 00 08 78 08 78 00 00 00 00 00 24 02 05 05 03 00 00 00 05 40 39 01 00 00 05 00 21 d5 20 20 19 19 18 18 02 03 00 01 24 24 18 18 18 18 24 24 00 00 00 00 00 00 00 00 2f 2f 30 30 31 31 39 01 00 00 05 00 21 d6 24 24 18 18 19 19 01 00 03 02 24 24 18 18 18 18 20 20 40 40 40 40 40 40 40 40 2f 2f 30 30 31 31 39 01 00 00 00 00 02 bd 00 39 01 00 00 00 00 11 d8 aa aa aa aa aa aa aa aa aa ba aa aa aa ba aa aa 39 01 00 00 00 00 02 bd 01 39 01 00 00 00 00 11 d8 00 00 00 00 00 00 00 00 82 ea aa aa 82 ea aa aa 39 01 00 00 00 00 02 bd 02 39 01 00 00 00 00 09 d8 ff ff c0 3f ff ff c0 3f 39 01 00 00 00 00 02 bd 00 39 01 00 00 05 00 37 e0 01 21 31 2d 66 6f 7b 75 7a 81 86 89 8c 90 95 97 9a a1 a2 aa 9e ad b0 5b 57 63 7a 01 21 31 2d 66 6f 7b 75 7a 81 86 89 8c 90 95 97 9a a1 a2 aa 9e ad b0 5b 57 63 7a 39 01 00 00 00 00 03 b6 7e 7e 39 01 00 00 00 00 02 cc 08 05 01 00 00 96 00 02 11 00 05 01 00 00 32 00 02 29 00];
				qcom,mdss-dsi-off-command = [05 01 00 00 32 00 02 28 00 05 01 00 00 96 00 02 10 00];
				qcom,mdss-dsi-bl-pmic-pwm-frequency = <0x64>;
				qcom,mdss-dsi-v-bottom-border = <0x00>;
				qcom,mdss-dsi-color-order = "rgb_swap_rgb";
				qcom,mdss-dsi-t-clk-pre = <0x31>;
				qcom,mdss-dsi-on-command-state = "dsi_lp_mode";
				qcom,mdss-dsi-h-back-porch = <0x30>;
				qcom,mdss-dsi-v-back-porch = <0x08>;
				qcom,mdss-dsi-panel-name = "hx8399c video mode dsi truly panel";
				qcom,mdss-dsi-lane-2-state;
				qcom,mdss-dsi-lp11-init;
				qcom,mdss-dsi-max-refresh-rate = <0x3c>;
				qcom,mdss-dsi-bllp-eof-power-mode;
				qcom,mdss-dsi-panel-status-check-mode = "reg_read";
				qcom,mdss-dsi-panel-width = <0x438>;
				qcom,mdss-dsi-h-sync-skew = <0x00>;
				qcom,mdss-dsi-reset-sequence = <0x01 0x0a 0x00 0x0a 0x01 0x0a>;
				qcom,mdss-dsi-panel-max-error-count = <0x03>;
				qcom,mdss-dsi-pan-enable-dynamic-fps;
				qcom,mdss-dsi-tx-eot-append;
				qcom,mdss-dsi-h-front-porch = <0x34>;
				qcom,mdss-dsi-v-front-porch = <0x08>;
				qcom,mdss-dsi-dma-trigger = "trigger_sw";
				qcom,mdss-dsi-v-top-border = <0x00>;
				qcom,mdss-dsi-pan-fps-update = "dfps_immediate_porch_mode_vfp";
				qcom,mdss-dsi-panel-status-command = <0x6010001 0x10a>;
				qcom,mdss-dsi-panel-height = <0x870>;
				qcom,mdss-dsi-h-sync-pulse = <0x00>;
				qcom,mdss-dsi-virtual-channel-id = <0x00>;
				qcom,mdss-dsi-lane-0-state;
				qcom,mdss-dsi-panel-timings-phy-v2 = <0x241f0809 0x50304a0 0x241f0809 0x50304a0 0x241f0809 0x50304a0 0x241f0809 0x50304a0 0x241c0809 0x50304a0>;
				qcom,mdss-dsi-underflow-color = <0xff>;
				qcom,mdss-dsi-panel-status-read-length = <0x04>;
				qcom,mdss-dsi-lane-3-state;
				qcom,mdss-dsi-h-left-border = <0x00>;
				qcom,mdss-dsi-border-color = <0x00>;
				qcom,mdss-pan-physical-width-dimension = <0x41>;
				qcom,mdss-dsi-panel-status-command-state = "dsi_lp_mode";
				qcom,mdss-dsi-mdp-trigger = "none";
				phandle = <0x2f9>;
				qcom,mdss-dsi-bpp = <0x18>;
				qcom,mdss-dsi-bl-pmic-bank-select = <0x00>;
				qcom,mdss-dsi-panel-type = "dsi_video_mode";
				qcom,mdss-dsi-lane-map = "lane_map_0123";
				qcom,mdss-dsi-panel-status-value = <0x9d 0x9d 0x9d 0x9d>;
				qcom,mdss-pan-physical-height-dimension = <0x81>;
				qcom,mdss-dsi-off-command-state = "dsi_hs_mode";
				qcom,mdss-dsi-panel-framerate = <0x3c>;
				qcom,mdss-dsi-lane-1-state;
				qcom,mdss-dsi-h-pulse-width = <0x08>;
				qcom,mdss-dsi-v-pulse-width = <0x04>;
				qcom,panel-supply-entries = <0x2e8>;
				qcom,mdss-dsi-bl-pmic-control-type = "bl_ctrl_pwm";
				qcom,mdss-dsi-min-refresh-rate = <0x30>;
				qcom,mdss-dsi-pwm-gpio = <0x14d 0x08 0x00>;
				qcom,mdss-dsi-stream = <0x00>;
				qcom,mdss-dsi-traffic-mode = "non_burst_sync_event";
				linux,phandle = <0x2f9>;
				qcom,mdss-dsi-panel-on-check-value = <0x9d 0x9d 0x9d 0x9d>;
				qcom,mdss-dsi-h-right-border = <0x00>;
				qcom,mdss-dsi-t-clk-post = <0x0e>;
			};

			qcom,mdss-reg-bus {
				qcom,msm-bus,num-paths = <0x01>;
				qcom,msm-bus,num-cases = <0x04>;
				qcom,msm-bus,vectors-KBps = <0x01 0x24e 0x00 0x00 0x01 0x24e 0x00 0x12c00 0x01 0x24e 0x00 0x27100 0x01 0x24e 0x00 0x4e200>;
				qcom,msm-bus,name = "mdss_reg";
				qcom,msm-bus,active-only;
			};

			smmu_mdp_unsec: qcom,smmu_mdp_unsec_cb {
				compatible = "qcom,smmu_mdp_unsec";
				phandle = <0x24f>;
				iommus = <0xa5 0xc00 0x00>;
				linux,phandle = <0x24f>;
			};
		};
